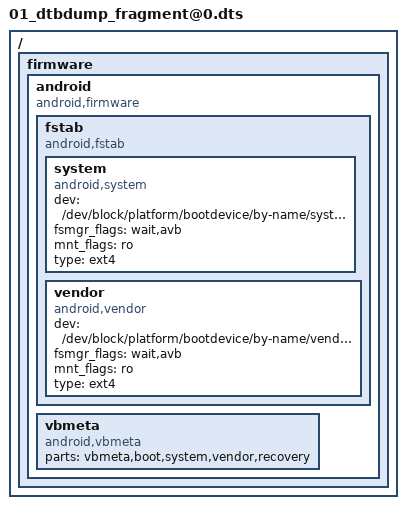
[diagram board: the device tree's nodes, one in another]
/dts-v1/;

/ {

	__fixups__ {
		accdet = "/fragment@20:target:0\0/fragment@61:target:0";
		apuart0 = "/fragment@25:target:0";
		audgpio = "/fragment@21:target:0";
		auxadc = "/fragment@40:target:0";
		charger = "/fragment@34:target:0";
		chosen = "/fragment@1:target:0";
		consys = "/fragment@24:target:0";
		dsi_te = "/fragment@66:target:0";
		egis_fp = "/fragment@4:target:0\0/fragment@64:target:0";
		gpio = "/fragment@55:target:0";
		gpio_usage_mapping = "/fragment@54:target:0";
		gyro = "/fragment@59:target:0";
		i2c0 = "/fragment@16:target:0\0/fragment@42:target:0";
		i2c1 = "/fragment@43:target:0";
		i2c10 = "/fragment@52:target:0";
		i2c11 = "/fragment@53:target:0";
		i2c2 = "/fragment@44:target:0";
		i2c3 = "/fragment@10:target:0\0/fragment@13:target:0\0/fragment@45:target:0";
		i2c4 = "/fragment@46:target:0";
		i2c5 = "/fragment@47:target:0";
		i2c6 = "/fragment@38:target:0\0/fragment@48:target:0";
		i2c7 = "/fragment@49:target:0";
		i2c8 = "/fragment@50:target:0";
		i2c9 = "/fragment@51:target:0";
		irtx_pwm = "/fragment@27:target:0";
		kd_camera_hw1 = "/fragment@78:target:0\0/fragment@82:target:0";
		keypad = "/fragment@30:target:0\0/fragment@80:target:0";
		main_pmic = "/fragment@67:target:0";
		md1_sim1_hot_plug_eint = "/fragment@69:target:0";
		md1_sim2_hot_plug_eint = "/fragment@70:target:0";
		mediatek_phy_tuning = "/fragment@8:target:0";
		mrdump_ext_rst = "/fragment@56:target:0";
		msdc1 = "/fragment@32:target:0";
		msdc1_ins = "/fragment@58:target:0";
		mse = "/fragment@60:target:0";
		mt6370_pmu = "/fragment@29:target:0";
		mt_pmic_vcama1_ldo_reg = "/fragment@71:target:0\0/fragment@78/__overlay__:vcama_main2-supply:0\0/fragment@82/__overlay__:cam2_vcama-supply:0";
		mt_pmic_vcama2_ldo_reg = "/fragment@72:target:0\0/fragment@78/__overlay__:vcama_sub-supply:0\0/fragment@82/__overlay__:cam1_vcama-supply:0";
		mt_pmic_vcamd_ldo_reg = "/fragment@75:target:0\0/fragment@78/__overlay__:vcamd-supply:0\0/fragment@82/__overlay__:cam0_vcamd-supply:0";
		mt_pmic_vcamio_ldo_reg = "/fragment@76:target:0\0/fragment@78/__overlay__:vcamio-supply:0\0/fragment@78/__overlay__:vcamio_sub-supply:0\0/fragment@78/__overlay__:vcamio_main2-supply:0\0/fragment@82/__overlay__:cam0_vcamio-supply:0\0/fragment@82/__overlay__:cam1_vcamio-supply:0\0/fragment@82/__overlay__:cam2_vcamio-supply:0";
		mt_pmic_vldo28_ldo_reg = "/fragment@77:target:0\0/fragment@78/__overlay__:vcamaf-supply:0\0/fragment@78/__overlay__:vcamaf_sub-supply:0\0/fragment@78/__overlay__:vcamaf_main2-supply:0\0/fragment@79/__overlay__:vtouch-supply:0\0/fragment@82/__overlay__:cam0_vcamaf-supply:0";
		mt_pmic_vsim1_ldo_reg = "/fragment@73:target:0";
		mt_pmic_vsim2_ldo_reg = "/fragment@74:target:0";
		mtkfb = "/fragment@12:target:0";
		odm = "/fragment@2:target:0";
		oppo_fp_common = "/fragment@7:target:0";
		otg_iddig = "/fragment@18:target:0\0/fragment@62:target:0";
		pio = "/fragment@2/__overlay__/kpd_volume_up:interrupt-parent:0\0/fragment@2/__overlay__/kpd_volume_down:interrupt-parent:0\0/fragment@2/__overlay__/oppo_devinfo:Hw,sub_hwid_1:0\0/fragment@2/__overlay__/oppo_charger:qcom,chargerid_switch-gpio:0\0/fragment@2/__overlay__/oppo_charger:qcom,ship-gpio:0\0/fragment@2/__overlay__/oppo_charger:qcom,shortc-gpio:0\0/fragment@5:target:0\0/fragment@6:target:0\0/fragment@7/__overlay__:oppo,fp-id0:0\0/fragment@11:target:0\0/fragment@14:target:0\0/fragment@15:target:0\0/fragment@16/__overlay__/dhall0-m1120@0f:interrupt-parent:0\0/fragment@16/__overlay__/dhall0-m1120@0f:dhall,irq-gpio:0\0/fragment@16/__overlay__/dhall0-m1120@0f:hall-power-gpio:0\0/fragment@16/__overlay__/dhall1-m1120@0c:interrupt-parent:0\0/fragment@16/__overlay__/dhall1-m1120@0c:dhall,irq-gpio:0\0/fragment@16/__overlay__/dhall1-m1120@0c:hall-power-gpio:0\0/fragment@17:target:0\0/fragment@19:target:0\0/fragment@22:target:0\0/fragment@23:target:0\0/fragment@26:target:0\0/fragment@28:target:0\0/fragment@29/__overlay__:mt6370,intr_gpio:0\0/fragment@30/__overlay__:keypad,volume-up:0\0/fragment@30/__overlay__:keypad,volume-down:0\0/fragment@31:target:0\0/fragment@33:target:0\0/fragment@35:target:0\0/fragment@36:target:0\0/fragment@37:target:0\0/fragment@39:target:0\0/fragment@43/__overlay__/alsps@51:interrupt-parent:0\0/fragment@54/__overlay__:GPIO_SIM2_SIO:0\0/fragment@54/__overlay__:GPIO_SIM2_SRST:0\0/fragment@54/__overlay__:GPIO_SIM2_SCLK:0\0/fragment@54/__overlay__:GPIO_SIM1_SCLK:0\0/fragment@54/__overlay__:GPIO_SIM1_SRST:0\0/fragment@54/__overlay__:GPIO_SIM1_SIO:0\0/fragment@54/__overlay__:GPIO_SIM2_HOT_PLUG:0\0/fragment@54/__overlay__:GPIO_SIM1_HOT_PLUG:0\0/fragment@54/__overlay__:GPIO_FDD_BAND_SUPPORT_DETECT_3RD_PIN:0\0/fragment@54/__overlay__:GPIO_FDD_BAND_SUPPORT_DETECT_1ST_PIN:0\0/fragment@54/__overlay__:GPIO_FDD_BAND_SUPPORT_DETECT_2ND_PIN:0\0/fragment@56/__overlay__:interrupt-parent:0\0/fragment@56/__overlay__:deb-gpios:0\0/fragment@57/__overlay__:interrupt-parent:0\0/fragment@58/__overlay__:interrupt-parent:0\0/fragment@58/__overlay__:deb-gpios:0\0/fragment@59/__overlay__:interrupt-parent:0\0/fragment@60/__overlay__:interrupt-parent:0\0/fragment@61/__overlay__:interrupt-parent:0\0/fragment@61/__overlay__:deb-gpios:0\0/fragment@62/__overlay__:interrupt-parent:0\0/fragment@63/__overlay__:interrupt-parent:0\0/fragment@64/__overlay__:interrupt-parent:0\0/fragment@65/__overlay__:interrupt-parent:0\0/fragment@66/__overlay__:interrupt-parent:0\0/fragment@67/__overlay__:interrupt-parent:0\0/fragment@68/__overlay__:interrupt-parent:0\0/fragment@81:target:0";
		pmic_clock_buffer_ctrl = "/fragment@41:target:0";
		reserved_memory = "/fragment@0:target:0";
		scp = "/fragment@9:target:0";
		smart_pa = "/fragment@68:target:0";
		spi0 = "/fragment@3:target:0";
		subpmic_pmu_eint = "/fragment@63:target:0";
		tcpc_pd = "/fragment@65:target:0";
		touch = "/fragment@57:target:0\0/fragment@79:target:0";
	};

	__local_fixups__ {

		fragment@12 {

			__overlay__ {
				pinctrl-0 = <0x00>;
				pinctrl-1 = <0x00>;
			};
		};

		fragment@13 {

			__overlay__ {

				tfa98xx@35 {
					pinctrl-0 = <0x00>;
					pinctrl-1 = <0x00>;
					pinctrl-2 = <0x00>;
				};
			};
		};

		fragment@16 {

			__overlay__ {

				dhall0-m1120@0f {
					pinctrl-0 = <0x00>;
					pinctrl-1 = <0x00>;
					pinctrl-2 = <0x00>;
				};

				dhall1-m1120@0c {
					pinctrl-0 = <0x00>;
					pinctrl-1 = <0x00>;
					pinctrl-2 = <0x00>;
				};
			};
		};

		fragment@18 {

			__overlay__ {
				pinctrl-0 = <0x00>;
				pinctrl-1 = <0x00>;
				pinctrl-2 = <0x00>;
				pinctrl-3 = <0x00>;
			};
		};

		fragment@2 {

			__overlay__ {

				oppo_charger {
					pinctrl-0 = <0x00>;
					pinctrl-1 = <0x00>;
					pinctrl-2 = <0x00>;
					pinctrl-3 = <0x00>;
					pinctrl-4 = <0x00>;
					pinctrl-5 = <0x00>;
				};

				oppo_devinfo {
					pinctrl-0 = <0x00>;
					pinctrl-1 = <0x00>;
					pinctrl-2 = <0x00>;
				};
			};
		};

		fragment@21 {

			__overlay__ {
				pinctrl-0 = <0x00>;
				pinctrl-1 = <0x00>;
				pinctrl-10 = <0x00>;
				pinctrl-11 = <0x00>;
				pinctrl-2 = <0x00>;
				pinctrl-3 = <0x00>;
				pinctrl-4 = <0x00>;
				pinctrl-5 = <0x00>;
				pinctrl-6 = <0x00>;
				pinctrl-7 = <0x00>;
				pinctrl-8 = <0x00>;
				pinctrl-9 = <0x00>;
			};
		};

		fragment@24 {

			__overlay__ {
				pinctrl-0 = <0x00>;
				pinctrl-1 = <0x00>;
				pinctrl-2 = <0x00>;
				pinctrl-3 = <0x00>;
			};
		};

		fragment@25 {

			__overlay__ {
				pinctrl-0 = <0x00>;
				pinctrl-1 = <0x00>;
				pinctrl-2 = <0x00>;
				pinctrl-3 = <0x00>;
				pinctrl-4 = <0x00>;
				pinctrl-5 = <0x00>;
				pinctrl-6 = <0x00>;
			};
		};

		fragment@27 {

			__overlay__ {
				pinctrl-0 = <0x00>;
				pinctrl-1 = <0x00>;
			};
		};

		fragment@30 {

			__overlay__ {
				pinctrl-0 = <0x00>;
				pinctrl-1 = <0x00>;
			};
		};

		fragment@32 {

			__overlay__ {
				pinctrl-0 = <0x00>;
				pinctrl-1 = <0x00>;
			};
		};

		fragment@38 {

			__overlay__ {
				pinctrl-0 = <0x00>;
				pinctrl-1 = <0x00>;
			};
		};

		fragment@4 {

			__overlay__ {
				pinctrl-0 = <0x00>;
				pinctrl-1 = <0x00>;
				pinctrl-2 = <0x00>;
				pinctrl-3 = <0x00>;
			};
		};

		fragment@7 {

			__overlay__ {
				pinctrl-0 = <0x00>;
			};
		};

		fragment@82 {

			__overlay__ {
				pinctrl-0 = <0x00>;
				pinctrl-1 = <0x00>;
				pinctrl-10 = <0x00>;
				pinctrl-11 = <0x00>;
				pinctrl-12 = <0x00>;
				pinctrl-13 = <0x00>;
				pinctrl-14 = <0x00>;
				pinctrl-15 = <0x00>;
				pinctrl-16 = <0x00>;
				pinctrl-17 = <0x00>;
				pinctrl-18 = <0x00>;
				pinctrl-19 = <0x00>;
				pinctrl-2 = <0x00>;
				pinctrl-20 = <0x00>;
				pinctrl-21 = <0x00>;
				pinctrl-22 = <0x00>;
				pinctrl-23 = <0x00>;
				pinctrl-24 = <0x00>;
				pinctrl-25 = <0x00>;
				pinctrl-26 = <0x00>;
				pinctrl-27 = <0x00>;
				pinctrl-28 = <0x00>;
				pinctrl-29 = <0x00>;
				pinctrl-3 = <0x00>;
				pinctrl-30 = <0x00>;
				pinctrl-31 = <0x00>;
				pinctrl-32 = <0x00>;
				pinctrl-33 = <0x00>;
				pinctrl-4 = <0x00>;
				pinctrl-5 = <0x00>;
				pinctrl-6 = <0x00>;
				pinctrl-7 = <0x00>;
				pinctrl-8 = <0x00>;
				pinctrl-9 = <0x00>;
			};
		};
	};

	__symbols__ {
		alsps_mtk = "/fragment@43/__overlay__/alsps@51";
		aud_clk_mosi_off = "/fragment@22/__overlay__/aud_clk_mosi_off";
		aud_clk_mosi_on = "/fragment@22/__overlay__/aud_clk_mosi_on";
		aud_dat_miso_off = "/fragment@22/__overlay__/aud_dat_miso_off";
		aud_dat_miso_on = "/fragment@22/__overlay__/aud_dat_miso_on";
		aud_dat_mosi_off = "/fragment@22/__overlay__/aud_dat_mosi_off";
		aud_dat_mosi_on = "/fragment@22/__overlay__/aud_dat_mosi_on";
		aud_extamp_pullhigh = "/fragment@22/__overlay__/aud_extamp_pullhigh";
		aud_extamp_pulllow = "/fragment@22/__overlay__/aud_extamp_pulllow";
		barometer_mtk = "/fragment@43/__overlay__/barometer@77";
		bat_gm30 = "/fragment@2/__overlay__/battery";
		camera_main_af_mtk = "/fragment@44/__overlay__/camera_main_af@72";
		camera_main_eeprom_mtk = "/fragment@44/__overlay__/camera_main_eeprom@50";
		camera_main_mtk = "/fragment@44/__overlay__/camera_main@1a";
		camera_main_two_af_mtk = "/fragment@46/__overlay__/camera_main_two_af@72";
		camera_main_two_eeprom_mtk = "/fragment@46/__overlay__/camera_main_two_eeprom@51";
		camera_main_two_mtk = "/fragment@46/__overlay__/camera_main_two@10";
		camera_pins_cam0_mclk_2ma = "/fragment@81/__overlay__/camera0_mclk_2mA@gpio99";
		camera_pins_cam0_mclk_4ma = "/fragment@81/__overlay__/camera0_mclk_4mA@gpio99";
		camera_pins_cam0_mclk_6ma = "/fragment@81/__overlay__/camera0_mclk_6mA@gpio99";
		camera_pins_cam0_mclk_8ma = "/fragment@81/__overlay__/camera0_mclk_8mA@gpio99";
		camera_pins_cam0_mclk_off = "/fragment@81/__overlay__/camera0_mclk_gpio_mode@gpio99";
		camera_pins_cam0_pnd_0 = "/fragment@81/__overlay__/cam0@2";
		camera_pins_cam0_pnd_1 = "/fragment@81/__overlay__/cam0@3";
		camera_pins_cam0_rst_0 = "/fragment@81/__overlay__/cam0@0";
		camera_pins_cam0_rst_1 = "/fragment@81/__overlay__/cam0@1";
		camera_pins_cam0_vcama_0 = "/fragment@81/__overlay__/cam0@vcam0";
		camera_pins_cam0_vcama_1 = "/fragment@81/__overlay__/cam0@vcam1";
		camera_pins_cam1_mclk_2ma = "/fragment@81/__overlay__/camera1_mclk_2mA@gpio100";
		camera_pins_cam1_mclk_4ma = "/fragment@81/__overlay__/camera1_mclk_4mA@gpio100";
		camera_pins_cam1_mclk_6ma = "/fragment@81/__overlay__/camera1_mclk_6mA@gpio100";
		camera_pins_cam1_mclk_8ma = "/fragment@81/__overlay__/camera1_mclk_8mA@gpio100";
		camera_pins_cam1_mclk_off = "/fragment@81/__overlay__/camera1_mclk_gpio_mode@gpio100";
		camera_pins_cam1_pdn_0 = "/fragment@81/__overlay__/cam1@0";
		camera_pins_cam1_pdn_1 = "/fragment@81/__overlay__/cam1@1";
		camera_pins_cam1_rst_0 = "/fragment@81/__overlay__/cam1@2";
		camera_pins_cam1_rst_1 = "/fragment@81/__overlay__/cam1@3";
		camera_pins_cam1_vcamd_0 = "/fragment@81/__overlay__/cam1@vcam0";
		camera_pins_cam1_vcamd_1 = "/fragment@81/__overlay__/cam1@vcam1";
		camera_pins_cam2_mclk_2ma = "/fragment@81/__overlay__/camera2_mclk_2mA@gpio108";
		camera_pins_cam2_mclk_4ma = "/fragment@81/__overlay__/camera2_mclk_4mA@gpio108";
		camera_pins_cam2_mclk_6ma = "/fragment@81/__overlay__/camera2_mclk_6mA@gpio108";
		camera_pins_cam2_mclk_8ma = "/fragment@81/__overlay__/camera2_mclk_8mA@gpio108";
		camera_pins_cam2_mclk_off = "/fragment@81/__overlay__/camera2_mclk_gpio_mode@gpio108";
		camera_pins_cam2_pnd_0 = "/fragment@81/__overlay__/cam2@3";
		camera_pins_cam2_pnd_1 = "/fragment@81/__overlay__/cam2@4";
		camera_pins_cam2_rst_0 = "/fragment@81/__overlay__/cam2@0";
		camera_pins_cam2_rst_1 = "/fragment@81/__overlay__/cam2@1";
		camera_pins_cami2c_pullup_disable = "/fragment@81/__overlay__/camera_pins_cami2c_pullup_disable@i2c";
		camera_pins_cami2c_pullup_enable = "/fragment@81/__overlay__/camera_pins_cami2c_pullup_enable@i2c";
		camera_pins_default = "/fragment@81/__overlay__/camdefault";
		camera_sub_eeprom_mtk = "/fragment@46/__overlay__/camera_sub_eeprom@54";
		camera_sub_mtk = "/fragment@46/__overlay__/camera_sub@35";
		cap_touch_mtk = "/fragment@42/__overlay__/cap_touch@5d";
		ccu_sensor_i2c_2_hw_mtk = "/fragment@44/__overlay__/ccu_sensor_i2c_2_hw@33";
		ccu_sensor_i2c_4_hw_mtk = "/fragment@46/__overlay__/ccu_sensor_i2c_4_hw@36";
		charger_pins_default = "/fragment@35/__overlay__/eint0default";
		charger_pins_eint_output0 = "/fragment@35/__overlay__/charger_gpio_as_output_low";
		charger_pins_eint_output1 = "/fragment@35/__overlay__/charger_gpio_as_output_high";
		charging_clock_active = "/fragment@36/__overlay__/charging_clock_active";
		charging_clock_sleep = "/fragment@36/__overlay__/charging_clock_sleep";
		charging_data_active = "/fragment@36/__overlay__/charging_data_active";
		charging_data_sleep = "/fragment@36/__overlay__/charging_data_sleep";
		charging_reset_active = "/fragment@36/__overlay__/charging_reset_active";
		charging_reset_sleep = "/fragment@36/__overlay__/charging_reset_sleep";
		charging_switch1_active = "/fragment@36/__overlay__/charging_switch1_active";
		charging_switch1_sleep = "/fragment@36/__overlay__/charging_switch1_sleep";
		consys_pins_default = "/fragment@23/__overlay__/consys_default";
		ctp_pins_default = "/fragment@15/__overlay__/eint0default";
		ctp_pins_eint_as_int = "/fragment@15/__overlay__/eint@0";
		ctp_pins_eint_output0 = "/fragment@15/__overlay__/eintoutput0";
		ctp_pins_eint_output1 = "/fragment@15/__overlay__/eintoutput1";
		ctp_pins_rst_output0 = "/fragment@15/__overlay__/rstoutput0";
		ctp_pins_rst_output1 = "/fragment@15/__overlay__/rstoutput1";
		fuelgauge = "/fragment@2/__overlay__/fuelgauge";
		gpio42_output_high = "/fragment@19/__overlay__/gpio42_output_high";
		gpio9_gpio_mode = "/fragment@19/__overlay__/id_output_low";
		gpio9_mode1_iddig = "/fragment@19/__overlay__/id_init";
		gpio_id0_default = "/fragment@6/__overlay__/gpio_id0_default";
		gpslna_pins_init = "/fragment@23/__overlay__/gpslna@0";
		gpslna_pins_oh = "/fragment@23/__overlay__/gpslna@1";
		gpslna_pins_ol = "/fragment@23/__overlay__/gpslna@2";
		hall0_interrupt_input = "/fragment@17/__overlay__/hall0_interrupt_input";
		hall1_interrupt_input = "/fragment@17/__overlay__/hall1_interrupt_input";
		hall_power_down = "/fragment@17/__overlay__/hall_power_down";
		hall_power_up = "/fragment@17/__overlay__/hall_power_up";
		hw_pins_default = "/fragment@37/__overlay__/default@hw_sub_id";
		hw_pins_sub_id1_active = "/fragment@37/__overlay__/active@id1";
		hw_pins_sub_id1_sleep = "/fragment@37/__overlay__/sleep@id1";
		i2c6_i2c_state = "/fragment@39/__overlay__/i2c6_sda_i2c_state";
		i2c6_output_low_state = "/fragment@39/__overlay__/i2c6_sda_output_low_state";
		iddig_default = "/fragment@19/__overlay__/iddig_default";
		irtx_gpio_led_default = "/fragment@28/__overlay__/irtx_gpio_led_def@gpio90";
		irtx_gpio_led_set = "/fragment@28/__overlay__/irtx_gpio_led_set@gpio90";
		kpd_volume_down = "/fragment@2/__overlay__/kpd_volume_down";
		kpd_volume_up = "/fragment@2/__overlay__/kpd_volume_up";
		led0 = "/fragment@2/__overlay__/led@0";
		led1 = "/fragment@2/__overlay__/led@1";
		led2 = "/fragment@2/__overlay__/led@2";
		led3 = "/fragment@2/__overlay__/led@3";
		led4 = "/fragment@2/__overlay__/led@4";
		led5 = "/fragment@2/__overlay__/led@5";
		led6 = "/fragment@2/__overlay__/led@6";
		msdc1_off = "/fragment@33/__overlay__/sd0@1";
		msdc1_on = "/fragment@33/__overlay__/sd0@0";
		msensor_mtk = "/fragment@43/__overlay__/msensor@0c";
		mtkfb_pins_lcd_1p8_en0 = "/fragment@11/__overlay__/lcd_1p8_en0_gpio";
		mtkfb_pins_lcd_1p8_en1 = "/fragment@11/__overlay__/lcd_1p8_en1_gpio";
		mtkfb_pins_lcd_bias_enn0 = "/fragment@11/__overlay__/lcd_bias_enn0_gpio";
		mtkfb_pins_lcd_bias_enn1 = "/fragment@11/__overlay__/lcd_bias_enn1_gpio";
		mtkfb_pins_lcd_bias_enp0 = "/fragment@11/__overlay__/lcd_bias_enp0_gpio";
		mtkfb_pins_lcd_bias_enp1 = "/fragment@11/__overlay__/lcd_bias_enp1_gpio";
		mtkfb_pins_lcd_bl_en0 = "/fragment@11/__overlay__/lcd_bl_en0_gpio";
		mtkfb_pins_lcd_bl_en1 = "/fragment@11/__overlay__/lcd_bl_en1_gpio";
		mtkfb_pins_lcm_reset0 = "/fragment@11/__overlay__/lcm_rst_out0_gpio";
		mtkfb_pins_lcm_reset1 = "/fragment@11/__overlay__/lcm_rst_out1_gpio";
		mtkfb_pins_mode_te_gpio = "/fragment@11/__overlay__/mode_te_gpio";
		mtkfb_pins_mode_te_te = "/fragment@11/__overlay__/mode_te_te";
		mtkfb_pins_spi_clk_en0 = "/fragment@11/__overlay__/spi_clk_en0_gpio";
		mtkfb_pins_spi_clk_en1 = "/fragment@11/__overlay__/spi_clk_en1_gpio";
		mtkfb_pins_spi_cs_en0 = "/fragment@11/__overlay__/spi_csn_en0_gpio";
		mtkfb_pins_spi_cs_en1 = "/fragment@11/__overlay__/spi_csn_en1_gpio";
		nfc_mtk = "/fragment@45/__overlay__/nfc@08";
		oppo_charger = "/fragment@2/__overlay__/oppo_charger";
		oppo_devinfo = "/fragment@2/__overlay__/oppo_devinfo";
		oppo_project = "/fragment@2/__overlay__/oppo_project";
		oppo_sensor = "/fragment@2/__overlay__/oppo_sensor";
		ship_active_gpio = "/fragment@35/__overlay__/ship_active";
		ship_sleep_gpio = "/fragment@35/__overlay__/ship_sleep";
		shortc_active_gpio = "/fragment@35/__overlay__/shortc_active";
		silfp_default = "/fragment@5/__overlay__/silfpdefault";
		silfp_irq = "/fragment@5/__overlay__/fp_eint@8";
		silfp_rst_high = "/fragment@5/__overlay__/state_reset_high";
		silfp_rst_low = "/fragment@5/__overlay__/state_reset_low";
		slave_charger_mtk = "/fragment@48/__overlay__/slave_charger@4b";
		speaker_amp_mtk = "/fragment@48/__overlay__/speaker_amp@34";
		subpmic_pmu_mtk = "/fragment@47/__overlay__/subpmic_pmu@34";
		tfa98xxresetdefault = "/fragment@14/__overlay__/tfa98xxrstdefault";
		tfa98xxresethigh = "/fragment@14/__overlay__/tfa98xxrsthigh";
		tfa98xxresetlow = "/fragment@14/__overlay__/tfa98xxrstlow";
		uart0_gpio_def_cfg = "/fragment@26/__overlay__/uart0gpiodefault";
		uart0_rx_clr_cfg = "/fragment@26/__overlay__/uart0_rx_clear@gpio95";
		uart0_rx_gpio_input = "/fragment@26/__overlay__/uart0_rx_gpio@gpio95";
		uart0_rx_set_cfg = "/fragment@26/__overlay__/uart0_rx_set@gpio95";
		uart0_tx_clr_cfg = "/fragment@26/__overlay__/uart0_tx_clear@gpio96";
		uart0_tx_gpio_input = "/fragment@26/__overlay__/uart0_tx_gpio@gpio96";
		uart0_tx_set_cfg = "/fragment@26/__overlay__/uart0_tx_set@gpio96";
		usb_c_pinctrl = "/fragment@2/__overlay__/usb_c_pinctrl";
		usb_type_c_mtk = "/fragment@47/__overlay__/usb_type_c@4e";
		vibrator0 = "/fragment@2/__overlay__/vibrator@0";
		volume_down_gpio_eint = "/fragment@31/__overlay__/volume_down@0";
		volume_up_gpio_eint = "/fragment@31/__overlay__/volume_up@0";
		vooc_ap_data = "/fragment@2/__overlay__/vooc_ap_data";
		vooc_ap_data_new_function = "/fragment@2/__overlay__/vooc_ap_data_new_function";
		vow_clk_miso_off = "/fragment@22/__overlay__/vow_clk_miso_off";
		vow_clk_miso_on = "/fragment@22/__overlay__/vow_clk_miso_on";
		vow_dat_miso_off = "/fragment@22/__overlay__/vow_dat_miso_off";
		vow_dat_miso_on = "/fragment@22/__overlay__/vow_dat_miso_on";
	};

	firmware {

		android {
			compatible = "android,firmware";

			fstab {
				compatible = "android,fstab";

				system {
					compatible = "android,system";
					dev = "/dev/block/platform/bootdevice/by-name/system";
					fsmgr_flags = "wait,avb";
					mnt_flags = "ro";
					type = "ext4";
				};

				vendor {
					compatible = "android,vendor";
					dev = "/dev/block/platform/bootdevice/by-name/vendor";
					fsmgr_flags = "wait,avb";
					mnt_flags = "ro";
					type = "ext4";
				};
			};

			vbmeta {
				compatible = "android,vbmeta";
				parts = "vbmeta,boot,system,vendor,recovery";
			};
		};
	};

	fragment@0 {
		target = <0xffffffff>;

		__overlay__ {
			#address-cells = <0x02>;
			#size-cells = <0x02>;
			ranges;

			zmc-default {
				alignment = <0x00 0x10000000>;
				alloc-ranges = <0x01 0x00 0x01 0x00>;
				compatible = "mediatek,zone_movable_cma";
				size = <0x00 0xffc00000>;
			};
		};
	};

	fragment@1 {
		target = <0xffffffff>;

		__overlay__ {
			atag,videolfb-fb_base_h = <0x00>;
			atag,videolfb-fb_base_l = "^`P";
			atag,videolfb-fps = <0x1770>;
			atag,videolfb-islcm_inited = <0x00>;
			atag,videolfb-islcmfound = <0x01>;
			atag,videolfb-lcmname = "nt35595_fhd_dsi_cmd_truly_nt50358_drv";
			atag,videolfb-vramSize = <0x17bb000>;
		};
	};

	fragment@10 {
		target = <0xffffffff>;

		__overlay__ {
			#address-cells = <0x01>;
			#size-cells = <0x00>;

			i2c_bl_lm3697@36 {
				compatible = "mediatek,i2c_bl_lm3697";
				reg = <0x36>;
				status = "okay";
			};

			i2c_lcd_bias@3e {
				compatible = "mediatek,i2c_lcd_bias";
				reg = <0x3e>;
				status = "okay";
			};
		};
	};

	fragment@11 {
		target = <0xffffffff>;

		__overlay__ {

			lcd_1p8_en0_gpio {
				phandle = <0x78>;

				pins_cmd_dat {
					output-low;
					pinmux = <0x2e00>;
					slew-rate = <0x01>;
				};
			};

			lcd_1p8_en1_gpio {
				phandle = <0x79>;

				pins_cmd_dat {
					output-high;
					pinmux = <0x2e00>;
					slew-rate = <0x01>;
				};
			};

			lcd_bias_enn0_gpio {
				phandle = <0x74>;

				pins_cmd_dat {
					output-low;
					pinmux = <0xb200>;
					slew-rate = <0x01>;
				};
			};

			lcd_bias_enn1_gpio {
				phandle = <0x75>;

				pins_cmd_dat {
					output-high;
					pinmux = <0xb200>;
					slew-rate = <0x01>;
				};
			};

			lcd_bias_enp0_gpio {
				phandle = <0x72>;

				pins_cmd_dat {
					output-low;
					pinmux = <0x9f00>;
					slew-rate = <0x01>;
				};
			};

			lcd_bias_enp1_gpio {
				phandle = <0x73>;

				pins_cmd_dat {
					output-high;
					pinmux = <0x9f00>;
					slew-rate = <0x01>;
				};
			};

			lcd_bl_en0_gpio {
				phandle = <0x76>;

				pins_cmd_dat {
					output-low;
					pinmux = <0xaf00>;
					slew-rate = <0x01>;
				};
			};

			lcd_bl_en1_gpio {
				phandle = <0x77>;

				pins_cmd_dat {
					output-high;
					pinmux = <0xaf00>;
					slew-rate = <0x01>;
				};
			};

			lcm_rst_out0_gpio {
				phandle = <0x0f>;

				pins_cmd_dat {
					output-low;
					pinmux = <0x2d00>;
					slew-rate = <0x01>;
				};
			};

			lcm_rst_out1_gpio {
				phandle = <0x10>;

				pins_cmd_dat {
					output-high;
					pinmux = <0x2d00>;
					slew-rate = <0x01>;
				};
			};

			mode_te_gpio {
				phandle = <0x70>;

				pins_cmd_dat {
					pinmux = <0x2c00>;
				};
			};

			mode_te_te {
				phandle = <0x71>;

				pins_cmd_dat {
					pinmux = <0x2c01>;
				};
			};

			spi_clk_en0_gpio {
				phandle = <0x7d>;

				pins_cmd_dat {
					output-low;
					pinmux = <0x1800>;
					slew-rate = <0x01>;
				};
			};

			spi_clk_en1_gpio {
				phandle = <0x7c>;

				pins_cmd_dat {
					drive-strength = <0x00>;
					pinmux = <0x1802>;
				};
			};

			spi_csn_en0_gpio {
				phandle = <0x7b>;

				pins_cmd_dat {
					output-low;
					pinmux = <0x1600>;
					slew-rate = <0x01>;
				};
			};

			spi_csn_en1_gpio {
				phandle = <0x7a>;

				pins_cmd_dat {
					drive-strength = <0x00>;
					output-high;
					pinmux = <0x1602>;
				};
			};
		};
	};

	fragment@12 {
		target = <0xffffffff>;

		__overlay__ {
			oppo_display_cabc_support;
			oppo_display_ffl_support;
			pinctrl-0 = <0x0f>;
			pinctrl-1 = <0x10>;
			pinctrl-names = "lcm_rst_out0_gpio\0lcm_rst_out1_gpio";
			status = "okay";
		};
	};

	fragment@13 {
		target = <0xffffffff>;

		__overlay__ {
			#address-cells = <0x01>;
			#size-cells = <0x00>;

			tfa98xx@35 {
				compatible = "nxp,tfa98xx";
				pinctrl-0 = <0x11>;
				pinctrl-1 = <0x12>;
				pinctrl-2 = <0x13>;
				pinctrl-names = "tfa98xx_reset_default\0tfa98xx_reset_high\0tfa98xx_reset_low";
				reg = <0x35>;
				status = "okay";
			};
		};
	};

	fragment@14 {
		target = <0xffffffff>;

		__overlay__ {

			tfa98xxrstdefault {
				phandle = <0x11>;
			};

			tfa98xxrsthigh {
				phandle = <0x12>;

				pins_cmd_dat {
					output-high;
					pinmux = <0x9c00>;
					slew-rate = <0x01>;
				};
			};

			tfa98xxrstlow {
				phandle = <0x13>;

				pins_cmd_dat {
					output-low;
					pinmux = <0x9c00>;
					slew-rate = <0x01>;
				};
			};
		};
	};

	fragment@15 {
		target = <0xffffffff>;

		__overlay__ {

			eint0default {
				phandle = <0x7e>;
			};

			eint@0 {
				phandle = <0x7f>;

				pins_cmd_dat {
					bias-disable;
					pinmux = <0x100>;
					slew-rate = <0x00>;
				};
			};

			eintoutput0 {
				phandle = <0x80>;

				pins_cmd_dat {
					output-low;
					pinmux = <0x100>;
					slew-rate = <0x01>;
				};
			};

			eintoutput1 {
				phandle = <0x81>;

				pins_cmd_dat {
					output-high;
					pinmux = <0x100>;
					slew-rate = <0x01>;
				};
			};

			rstoutput0 {
				phandle = <0x82>;

				pins_cmd_dat {
					output-low;
					pinmux = <0x200>;
					slew-rate = <0x01>;
				};
			};

			rstoutput1 {
				phandle = <0x83>;

				pins_cmd_dat {
					output-high;
					pinmux = <0x200>;
					slew-rate = <0x01>;
				};
			};
		};
	};

	fragment@16 {
		target = <0xffffffff>;

		__overlay__ {
			status = "ok";

			dhall0-m1120@0f {
				compatible = "oppo,dhall-m1120";
				dhall,id = <0x00>;
				dhall,irq-gpio = <0xffffffff 0x05 0x2008>;
				hall-power-gpio = <0xffffffff 0x6e 0x00>;
				interrupt-parent = <0xffffffff>;
				interrupts = <0x05 0x08 0x05 0x00>;
				pinctrl-0 = <0x14>;
				pinctrl-1 = <0x15>;
				pinctrl-2 = <0x16>;
				pinctrl-names = "hall_power_down\0hall_power_up\0hall0_interrupt_input";
				reg = <0x0f>;
				status = "okay";
			};

			dhall1-m1120@0c {
				compatible = "oppo,dhall-m1120";
				dhall,id = <0x01>;
				dhall,irq-gpio = <0xffffffff 0x06 0x2008>;
				hall-power-gpio = <0xffffffff 0x6e 0x00>;
				interrupt-parent = <0xffffffff>;
				interrupts = <0x06 0x08 0x06 0x00>;
				pinctrl-0 = <0x14>;
				pinctrl-1 = <0x15>;
				pinctrl-2 = <0x17>;
				pinctrl-names = "hall_power_down\0hall_power_up\0hall1_interrupt_input";
				reg = <0x0c>;
				status = "okay";
			};
		};
	};

	fragment@17 {
		target = <0xffffffff>;

		__overlay__ {

			hall0_interrupt_input {
				phandle = <0x16>;

				pins_cmd_dat {
					bias-disable;
					drive-strength = <0x02>;
					pinmux = <0x600>;
					slew-rate = <0x00>;
				};
			};

			hall1_interrupt_input {
				phandle = <0x17>;

				pins_cmd_dat {
					bias-disable;
					drive-strength = <0x02>;
					pinmux = <0x500>;
					slew-rate = <0x00>;
				};
			};

			hall_power_down {
				phandle = <0x14>;

				pins_cmd_dat {
					bias-pull-down;
					drive-strength = <0x02>;
					output-low;
					pinmux = <0x6e00>;
					slew-rate = <0x01>;
				};
			};

			hall_power_up {
				phandle = <0x15>;

				pins_cmd_dat {
					bias-pull-down;
					drive-strength = <0x02>;
					output-high;
					pinmux = <0x6e00>;
					slew-rate = <0x01>;
				};
			};
		};
	};

	fragment@18 {
		target = <0xffffffff>;

		__overlay__ {
			compatible = "mediatek,usb_iddig_bi_eint";
			pinctrl-0 = <0x18>;
			pinctrl-1 = <0x19>;
			pinctrl-2 = <0x1a>;
			pinctrl-3 = <0x1b>;
			pinctrl-names = "iddig_default\0id_init\0id_output_low\0gpio42_output_high";
			qcom,otg_switch_gpio = <0x09>;
			status = "okay";
		};
	};

	fragment@19 {
		target = <0xffffffff>;

		__overlay__ {

			gpio42_output_high {
				phandle = <0x1b>;

				pins_cmd_dat {
					output-high;
					pinmux = <0x2a00>;
					slew-rate = <0x01>;
				};
			};

			id_init {
				phandle = <0x19>;

				pins_cmd_dat {
					pinmux = <0x900>;
					slew-rate = <0x00>;
				};
			};

			id_output_low {
				phandle = <0x1a>;

				pins_cmd_dat {
					output-low;
					pinmux = <0x900>;
					slew-rate = <0x01>;
				};
			};

			iddig_default {
				phandle = <0x18>;
			};
		};
	};

	fragment@2 {
		target = <0xffffffff>;

		__overlay__ {

			battery {
				CAR_TUNE_VALUE = <0x64>;
				DIFFERENCE_FULLOCV_ITH = <0xc8>;
				EMBEDDED_SEL = <0x01>;
				FG_METER_RESISTANCE = <0x4b>;
				KEEP_100_PERCENT = <0x02>;
				PMIC_MIN_VOL = <0x84d0>;
				PMIC_SHUTDOWN_CURRENT = <0x14>;
				POWERON_SYSTEM_IBOOT = <0x1f4>;
				Q_MAX_SYS_VOLTAGE_BAT0 = <0xd16>;
				Q_MAX_SYS_VOLTAGE_BAT1 = <0xd16>;
				Q_MAX_SYS_VOLTAGE_BAT2 = <0xd16>;
				Q_MAX_SYS_VOLTAGE_BAT3 = <0xd16>;
				R_FG_VALUE = <0x0a>;
				SHUTDOWN_1_TIME = <0x1e>;
				SHUTDOWN_GAUGE0_VOLTAGE = <0x84d0>;
				TEMPERATURE_T0 = <0x32>;
				TEMPERATURE_T1 = <0x19>;
				TEMPERATURE_T2 = <0x0a>;
				TEMPERATURE_T3 = <0x00>;
				TEMPERATURE_T4 = <0xfffffff6>;
				battery0_profile_t0 = <0x00 0xaa96 0x406 0x1a9 0xaa0e 0x402 0x352 0xa994 0x413 0x4fb 0xa91d 0x41a 0x6a5 0xa8a2 0x410 0x84e 0xa827 0x407 0x9f7 0xa7b8 0x41d 0xba0 0xa741 0x432 0xd49 0xa6c2 0x40b 0xef2 0xa649 0x411 0x109c 0xa5d2 0x41a 0x1245 0xa55e 0x423 0x13ee 0xa4ed 0x433 0x1597 0xa476 0x432 0x1740 0xa3ff 0x41c 0x18e9 0xa390 0x42d 0x1a92 0xa31b 0x433 0x1c3c 0xa2a9 0x433 0x1de5 0xa23a 0x43b 0x1f8e 0xa1cc 0x44c 0x2137 0xa15d 0x44c 0x22e0 0xa0ef 0x44c 0x2489 0xa07e 0x44c 0x2632 0xa015 0x45a 0x27dc 0x9faf 0x465 0x2985 0x9f46 0x45e 0x2b2e 0x9eda 0x452 0x2cd7 0x9e7c 0x47d 0x2e80 0x9e1f 0x47e 0x3029 0x9dbb 0x47e 0x31d3 0x9d5a 0x48b 0x337c 0x9cf8 0x497 0x3525 0x9c97 0x49d 0x36ce 0x9c42 0x4b0 0x3877 0x9bed 0x4b0 0x3a20 0x9ba0 0x4d7 0x3bc9 0x9b4d 0x4f2 0x3d73 0x9af8 0x4fb 0x3f1c 0x9aa3 0x503 0x40c5 0x9a4c 0x519 0x426e 0x99ee 0x52b 0x4417 0x9976 0x4eb 0x45c0 0x98e9 0x499 0x476a 0x986a 0x452 0x4913 0x9805 0x433 0x4abc 0x97b2 0x433 0x4c65 0x9767 0x430 0x4e0e 0x9723 0x41a 0x4fb7 0x96e8 0x41a 0x5160 0x96ac 0x41a 0x530a 0x9676 0x41a 0x54b3 0x9643 0x424 0x565c 0x9610 0x42d 0x5805 0x95dd 0x41c 0x59ae 0x95aa 0x431 0x5b57 0x957f 0x433 0x5d00 0x9554 0x433 0x5eaa 0x952a 0x43f 0x6053 0x9502 0x44c 0x61fc 0x94df 0x44c 0x63a5 0x94b4 0x44d 0x654e 0x9492 0x462 0x66f7 0x9470 0x477 0x68a1 0x9454 0x48d 0x6a4a 0x9436 0x497 0x6bf3 0x9414 0x497 0x6d9c 0x93f3 0x49b 0x6f45 0x93da 0x4b0 0x70ee 0x93b8 0x4b0 0x7297 0x9387 0x49e 0x7441 0x9343 0x46d 0x75ea 0x92fb 0x44c 0x7793 0x92bc 0x44c 0x793c 0x928a 0x44c 0x7ae5 0x9260 0x44c 0x7c8e 0x9235 0x44c 0x7e38 0x9204 0x43b 0x7fe1 0x91db 0x440 0x818a 0x91b9 0x44c 0x8333 0x9197 0x451 0x84dc 0x9174 0x463 0x8685 0x9141 0x44e 0x882e 0x9106 0x44c 0x89d8 0x90cb 0x44c 0x8b81 0x9094 0x458 0x8d2a 0x9058 0x45d 0x8ed3 0x900d 0x444 0x907c 0x8fca 0x41a 0x9225 0x8fb9 0x430 0x93ce 0x8faf 0x445 0x9578 0x8fa6 0x468 0x9721 0x8f95 0x493 0x98ca 0x8f71 0x4bd 0x9a73 0x8f18 0x4d6 0x9c1c 0x8e08 0x481 0x9dc5 0x8c44 0x492 0x9f6f 0x89fa 0x4c9 0xa118 0x86c7 0x523 0xa2c1 0x815c 0x76e 0xa46a 0x774c 0x18e7>;
				battery0_profile_t0_num = <0x64>;
				battery0_profile_t1 = <0x00 0xaa32 0x564 0x1a9 0xa9a1 0x560 0x352 0xa91f 0x55f 0x4fb 0xa8a5 0x56d 0x6a5 0xa82a 0x56e 0x84e 0xa7af 0x565 0x9f7 0xa740 0x578 0xba0 0xa6c9 0x578 0xd49 0xa652 0x578 0xef2 0xa5db 0x578 0x109c 0xa564 0x578 0x1245 0xa4f0 0x578 0x13ee 0xa47f 0x578 0x1597 0xa409 0x579 0x1740 0xa39a 0x58f 0x18e9 0xa32c 0x591 0x1a92 0xa2bd 0x5a0 0x1c3c 0xa24f 0x5aa 0x1de5 0xa1dd 0x5aa 0x1f8e 0xa169 0x5ae 0x2137 0xa103 0x5c3 0x22e0 0xa095 0x5c3 0x2489 0xa02b 0x5d5 0x2632 0x9fbf 0x5dc 0x27dc 0x9f59 0x5dc 0x2985 0x9efe 0x5ea 0x2b2e 0x9ea7 0x611 0x2cd7 0x9e41 0x626 0x2e80 0x9dd2 0x63c 0x3029 0x9d64 0x640 0x31d3 0x9cfb 0x64d 0x337c 0x9c98 0x662 0x3525 0x9c3b 0x672 0x36ce 0x9bdf 0x676 0x3877 0x9b92 0x6a1 0x3a20 0x9b3e 0x6a4 0x3bc9 0x9aef 0x6a4 0x3d73 0x9aa3 0x6bc 0x3f1c 0x9a49 0x6c5 0x40c5 0x99d3 0x68d 0x426e 0x9943 0x623 0x4417 0x98bb 0x5b9 0x45c0 0x9849 0x573 0x476a 0x97f2 0x55f 0x4913 0x97a5 0x554 0x4abc 0x975e 0x546 0x4c65 0x9721 0x543 0x4e0e 0x96dd 0x52d 0x4fb7 0x96a2 0x52d 0x5160 0x966d 0x52d 0x530a 0x963a 0x53a 0x54b3 0x960b 0x550 0x565c 0x95de 0x559 0x5805 0x95ac 0x548 0x59ae 0x9581 0x55d 0x5b57 0x9557 0x55f 0x5d00 0x952c 0x55f 0x5eaa 0x9507 0x56b 0x6053 0x94e4 0x580 0x61fc 0x94c2 0x591 0x63a5 0x94a0 0x592 0x654e 0x947e 0x5a7 0x66f7 0x945c 0x5aa 0x68a1 0x9440 0x5b9 0x6a4a 0x9427 0x5ce 0x6bf3 0x940a 0x5d4 0x6d9c 0x93e8 0x5bf 0x6f45 0x93c6 0x5aa 0x70ee 0x93ac 0x5c0 0x7297 0x9384 0x5b1 0x7441 0x935a 0x59c 0x75ea 0x932f 0x587 0x7793 0x9305 0x578 0x793c 0x92da 0x575 0x7ae5 0x92b0 0x560 0x7c8e 0x928d 0x573 0x7e38 0x926b 0x578 0x7fe1 0x9249 0x578 0x818a 0x9227 0x581 0x8333 0x9201 0x591 0x84dc 0x91ce 0x591 0x8685 0x9192 0x591 0x882e 0x9156 0x57e 0x89d8 0x9121 0x597 0x8b81 0x90e0 0x59e 0x8d2a 0x9094 0x581 0x8ed3 0x9053 0x563 0x907c 0x9042 0x579 0x9225 0x9039 0x5a3 0x93ce 0x902a 0x5ce 0x9578 0x9013 0x5f8 0x9721 0x8fed 0x62d 0x98ca 0x8f7c 0x645 0x9a73 0x8e67 0x611 0x9c1c 0x8c93 0x626 0x9dc5 0x8a1c 0x68d 0x9f6f 0x8685 0x72a 0xa118 0x7f7d 0x144e 0xa2c1 0x78a0 0x203a 0xa46a 0x78a0 0x203a>;
				battery0_profile_t1_num = <0x64>;
				battery0_profile_t2 = <0x00 0xa956 0x834 0x1a9 0xa8a3 0x834 0x352 0xa80d 0x846 0x4fb 0xa787 0x84d 0x6a5 0xa70c 0x857 0x84e 0xa695 0x866 0x9f7 0xa61d 0x863 0xba0 0xa59d 0x84e 0xd49 0xa52e 0x875 0xef2 0xa4b9 0x86f 0x109c 0xa442 0x866 0x1245 0xa3ce 0x878 0x13ee 0xa360 0x898 0x1597 0xa2f1 0x899 0x1740 0xa282 0x8af 0x18e9 0xa214 0x8b1 0x1a92 0xa1a5 0x8c0 0x1c3c 0xa137 0x8ca 0x1de5 0xa0c8 0x8d2 0x1f8e 0xa05b 0x8e3 0x2137 0x9ff5 0x8e3 0x22e0 0x9f98 0x8f8 0x2489 0x9f41 0x91f 0x2632 0x9eec 0x958 0x27dc 0x9e8f 0x98d 0x2985 0x9e1f 0x9a5 0x2b2e 0x9d96 0x98f 0x2cd7 0x9d05 0x97a 0x2e80 0x9c85 0x979 0x3029 0x9c20 0x989 0x31d3 0x9bd1 0x9ab 0x337c 0x9b8d 0x9c4 0x3525 0x9b43 0x9be 0x36ce 0x9aee 0x9ab 0x3877 0x9a99 0x9ab 0x3a20 0x9a44 0x9ab 0x3bc9 0x99dc 0x97c 0x3d73 0x9964 0x930 0x3f1c 0x98e8 0x8e3 0x40c5 0x9874 0x8a3 0x426e 0x980f 0x865 0x4417 0x97ba 0x850 0x45c0 0x976c 0x83b 0x476a 0x972b 0x843 0x4913 0x96eb 0x842 0x4abc 0x96aa 0x834 0x4c65 0x9670 0x837 0x4e0e 0x963d 0x84d 0x4fb7 0x960a 0x84d 0x5160 0x95d7 0x84d 0x530a 0x95a9 0x85a 0x54b3 0x957f 0x866 0x565c 0x9554 0x86c 0x5805 0x952b 0x881 0x59ae 0x9509 0x896 0x5b57 0x94df 0x898 0x5d00 0x94bb 0x8a8 0x5eaa 0x9499 0x8b1 0x6053 0x947a 0x8c2 0x61fc 0x945e 0x8e3 0x63a5 0x943d 0x8e4 0x654e 0x9423 0x8f9 0x66f7 0x9402 0x8fc 0x68a1 0x93ec 0x919 0x6a4a 0x93d2 0x923 0x6bf3 0x93b6 0x915 0x6d9c 0x93a4 0x919 0x6f45 0x938a 0x92e 0x70ee 0x9379 0x943 0x7297 0x935a 0x936 0x7441 0x9338 0x92e 0x75ea 0x9316 0x938 0x7793 0x92f4 0x947 0x793c 0x92d1 0x947 0x7ae5 0x92a6 0x947 0x7c8e 0x928c 0x970 0x7e38 0x925e 0x98a 0x7fe1 0x922b 0x9ac 0x818a 0x91f5 0x9cd 0x8333 0x91b9 0x9dd 0x84dc 0x917e 0x9e2 0x8685 0x9142 0xa22 0x882e 0x90f7 0xa4e 0x89d8 0x90ab 0xa69 0x8b81 0x907a 0xa96 0x8d2a 0x9064 0xade 0x8ed3 0x9051 0xb33 0x907c 0x9038 0xb89 0x9225 0x901e 0xc33 0x93ce 0x8fef 0xd01 0x9578 0x8f3f 0xd9d 0x9721 0x8dd8 0xe5b 0x98ca 0x8bb3 0xf90 0x9a73 0x88cc 0x1171 0x9c1c 0x8494 0x14ae 0x9dc5 0x7b3a 0x23d8 0x9f6f 0x78d2 0x23dc 0xa118 0x78d2 0x23dc 0xa2c1 0x78d2 0x23dc 0xa46a 0x78d2 0x23dc>;
				battery0_profile_t2_num = <0x64>;
				battery0_profile_t3 = <0x00 0xa866 0xd02 0x1a9 0xa71a 0xcfe 0x352 0xa65b 0xdf2 0x4fb 0xa5c4 0xe69 0x6a5 0xa53c 0xe88 0x84e 0xa4bf 0xeac 0x9f7 0xa449 0xec4 0xba0 0xa3da 0xeef 0xd49 0xa364 0xef1 0xef2 0xa2f3 0xf01 0x109c 0xa285 0xf17 0x1245 0xa216 0xf2c 0x13ee 0xa1a8 0xf41 0x1597 0xa139 0xf55 0x1740 0xa0ca 0xf55 0x18e9 0xa05c 0xf55 0x1a92 0x9ff9 0xf64 0x1c3c 0x9fa0 0xf90 0x1de5 0x9f4f 0xfdf 0x1f8e 0x9efd 0x103a 0x2137 0x9e97 0x104f 0x22e0 0x9e0f 0x1024 0x2489 0x9d6f 0x100b 0x2632 0x9cd8 0x1004 0x27dc 0x9c54 0x1004 0x2985 0x9be3 0x100b 0x2b2e 0x9b80 0x101d 0x2cd7 0x9b34 0x101d 0x2e80 0x9af0 0x1046 0x3029 0x9a9e 0x102d 0x31d3 0x9a49 0x1010 0x337c 0x99e9 0xfde 0x3525 0x997a 0xf8f 0x36ce 0x990c 0xf51 0x3877 0x98a6 0xf26 0x3a20 0x9840 0xefc 0x3bc9 0x97e1 0xee1 0x3d73 0x978d 0xecc 0x3f1c 0x9743 0xec7 0x40c5 0x96ff 0xed8 0x426e 0x96bc 0xed8 0x4417 0x9680 0xed8 0x45c0 0x964c 0xefd 0x476a 0x9619 0xf19 0x4913 0x95e6 0xf2e 0x4abc 0x95b6 0xf4a 0x4c65 0x958b 0xf6e 0x4e0e 0x9561 0xf6e 0x4fb7 0x9536 0xf98 0x5160 0x950c 0xfb1 0x530a 0x94e7 0xfd4 0x54b3 0x94c1 0xff5 0x565c 0x9499 0x100a 0x5805 0x9477 0x1021 0x59ae 0x945e 0x104c 0x5b57 0x943d 0x1063 0x5d00 0x9421 0x1088 0x5eaa 0x9407 0x10b2 0x6053 0x93f1 0x10e5 0x61fc 0x93e0 0x1120 0x63a5 0x93cf 0x114b 0x654e 0x93be 0x1175 0x66f7 0x93ad 0x11b2 0x68a1 0x9396 0x11d5 0x6a4a 0x937d 0x11f5 0x6bf3 0x9363 0x1228 0x6d9c 0x9349 0x1268 0x6f45 0x9330 0x12a8 0x70ee 0x930e 0x12e8 0x7297 0x92e4 0x1327 0x7441 0x92c0 0x1383 0x75ea 0x9295 0x13d9 0x7793 0x9262 0x1426 0x793c 0x922e 0x1490 0x7ae5 0x91f3 0x14fa 0x7c8e 0x91b7 0x158d 0x7e38 0x917c 0x1611 0x7fe1 0x9136 0x169e 0x818a 0x90e6 0x172d 0x8333 0x909b 0x17c6 0x84dc 0x9072 0x1896 0x8685 0x9059 0x1995 0x882e 0x903f 0x1abb 0x89d8 0x901f 0x1c22 0x8b81 0x8ff9 0x1dcf 0x8d2a 0x8fa2 0x1fba 0x8ed3 0x8ecf 0x21ce 0x907c 0x8d2a 0x23ea 0x9225 0x8abd 0x27bc 0x93ce 0x8747 0x2d83 0x9578 0x8203 0x3212 0x9721 0x7a1c 0x3264 0x98ca 0x7a1c 0x3264 0x9a73 0x7a1c 0x3264 0x9c1c 0x7a1c 0x3264 0x9dc5 0x7a1c 0x3264 0x9f6f 0x7a1c 0x3264 0xa118 0x7a1c 0x3264 0xa2c1 0x7a1c 0x3264 0xa46a 0x7a1c 0x3264>;
				battery0_profile_t3_num = <0x64>;
				battery0_profile_t4 = <0x00 0xa6c2 0x1c0c 0x1a9 0xa5e5 0x1c08 0x352 0xa508 0x1cc8 0x4fb 0xa41a 0x1d88 0x6a5 0xa330 0x1e5a 0x84e 0xa262 0x1f66 0x9f7 0xa1bd 0x207b 0xba0 0xa13d 0x20fb 0xd49 0xa0c6 0x212a 0xef2 0xa055 0x2165 0x109c 0x9ff1 0x21be 0x1245 0x9f93 0x2205 0x13ee 0x9f32 0x2229 0x1597 0x9ec1 0x2274 0x1740 0x9e30 0x221f 0x18e9 0x9d91 0x21ef 0x1a92 0x9ce9 0x21d4 0x1c3c 0x9c4d 0x21ca 0x1de5 0x9bc2 0x21c2 0x1f8e 0x9b44 0x21a9 0x2137 0x9acd 0x217f 0x22e0 0x9a67 0x2194 0x2489 0x9a08 0x2175 0x2632 0x99ab 0x2166 0x27dc 0x994d 0x2152 0x2985 0x98f2 0x212e 0x2b2e 0x989d 0x211e 0x2cd7 0x9848 0x2133 0x2e80 0x97fa 0x20f6 0x3029 0x97ad 0x211c 0x31d3 0x9760 0x2127 0x337c 0x9718 0x2137 0x3525 0x96d6 0x2171 0x36ce 0x969b 0x21a0 0x3877 0x9668 0x21f5 0x3a20 0x962d 0x21e8 0x3bc9 0x95f8 0x2212 0x3d73 0x95c5 0x223a 0x3f1c 0x9592 0x223f 0x40c5 0x9561 0x2240 0x426e 0x9536 0x2295 0x4417 0x950c 0x22ea 0x45c0 0x94e1 0x22f6 0x476a 0x94bd 0x2330 0x4913 0x949b 0x239b 0x4abc 0x947b 0x2406 0x4c65 0x9462 0x244d 0x4e0e 0x9448 0x24b6 0x4fb7 0x942f 0x24f7 0x5160 0x941c 0x2547 0x530a 0x9406 0x25aa 0x54b3 0x93f0 0x2627 0x565c 0x93dd 0x26a5 0x5805 0x93c3 0x26e0 0x59ae 0x93aa 0x26f5 0x5b57 0x9390 0x276d 0x5d00 0x9371 0x280c 0x5eaa 0x9353 0x28b6 0x6053 0x9333 0x2936 0x61fc 0x930a 0x299c 0x63a5 0x92e8 0x2a84 0x654e 0x92b5 0x2b43 0x66f7 0x9282 0x2c15 0x68a1 0x924f 0x2cbd 0x6a4a 0x9217 0x2d45 0x6bf3 0x91dc 0x2de8 0x6d9c 0x919f 0x2edf 0x6f45 0x915b 0x3009 0x70ee 0x9117 0x3132 0x7297 0x90da 0x326d 0x7441 0x90a9 0x339a 0x75ea 0x9082 0x351b 0x7793 0x9060 0x36e5 0x793c 0x903c 0x3856 0x7ae5 0x9008 0x3a08 0x7c8e 0x8fa4 0x3bbb 0x7e38 0x8edb 0x3d1c 0x7fe1 0x8d6b 0x3e12 0x818a 0x8b3a 0x3f5d 0x8333 0x883e 0x40e1 0x84dc 0x8396 0x40e2 0x8685 0x79c2 0x40e2 0x882e 0x79c2 0x40e2 0x89d8 0x79c2 0x40e2 0x8b81 0x79c2 0x40e2 0x8d2a 0x79c2 0x40e2 0x8ed3 0x79c2 0x40e2 0x907c 0x79c2 0x40e2 0x9225 0x79c2 0x40e2 0x93ce 0x79c2 0x40e2 0x9578 0x79c2 0x40e2 0x9721 0x79c2 0x40e2 0x98ca 0x79c2 0x40e2 0x9a73 0x79c2 0x40e2 0x9c1c 0x79c2 0x40e2 0x9dc5 0x79c2 0x40e2 0x9f6f 0x79c2 0x40e2 0xa118 0x79c2 0x40e2 0xa2c1 0x79c2 0x40e2 0xa46a 0x79c2 0x40e2>;
				battery0_profile_t4_num = <0x64>;
				battery1_profile_t0 = <0x00 0xa942 0x5aa 0x1a4 0xa8ab 0x5aa 0x348 0xa821 0x5bb 0x4ec 0xa79b 0x5b6 0x690 0xa71c 0x5b3 0x834 0xa6a4 0x5be 0x9d8 0xa626 0x5aa 0xb7c 0xa5b1 0x5aa 0xd20 0xa53b 0x5bc 0xec4 0xa4c6 0x5b5 0x1068 0xa454 0x5b4 0x120c 0xa3e4 0x5bd 0x13b0 0xa370 0x5ac 0x1554 0xa302 0x5c1 0x16f8 0xa295 0x5c3 0x189c 0xa228 0x5c3 0x1a40 0xa1b6 0x5b8 0x1be4 0xa146 0x5b1 0x1d88 0xa0e0 0x5c3 0x1f2c 0xa073 0x5c3 0x20d0 0xa00e 0x5c3 0x2274 0x9fa9 0x5c3 0x2418 0x9f43 0x5cf 0x25bc 0x9edd 0x5d3 0x2760 0x9e7a 0x5c7 0x2904 0x9e1e 0x5dd 0x2aa8 0x9dc1 0x5f2 0x2c4c 0x9d65 0x5f5 0x2df0 0x9d09 0x5f5 0x2f94 0x9cac 0x5f5 0x3138 0x9c52 0x5f5 0x32dc 0x9bfe 0x5f5 0x3480 0x9baa 0x5f5 0x3624 0x9b5d 0x61a 0x37c8 0x9b12 0x627 0x396c 0x9ac6 0x632 0x3b10 0x9a7b 0x647 0x3cb4 0x9a2e 0x659 0x3e58 0x99da 0x659 0x3ffc 0x998e 0x66d 0x41a0 0x9942 0x682 0x4344 0x98e9 0x68b 0x44e8 0x9878 0x666 0x468c 0x97f4 0x607 0x4830 0x977f 0x5dd 0x49d4 0x9722 0x5b3 0x4b78 0x96d9 0x5aa 0x4d1c 0x969b 0x5b7 0x4ec0 0x9660 0x5ba 0x5064 0x9627 0x5aa 0x5208 0x95f5 0x5aa 0x53ac 0x95c2 0x5aa 0x5550 0x9597 0x5bc 0x56f4 0x9568 0x5b5 0x5898 0x9539 0x5aa 0x5a3c 0x9511 0x5aa 0x5be0 0x94f0 0x5ac 0x5d84 0x94ce 0x5c1 0x5f28 0x94a5 0x5c3 0x60cc 0x9481 0x5c3 0x6270 0x9463 0x5ce 0x6414 0x9448 0x5dc 0x65b8 0x9427 0x5df 0x675c 0x940e 0x5f4 0x6900 0x93ed 0x5e2 0x6aa4 0x93d1 0x5ec 0x6c48 0x93b8 0x5f5 0x6dec 0x939e 0x5fd 0x6f90 0x9384 0x60e 0x7134 0x9362 0x60e 0x72d8 0x931f 0x5cf 0x747c 0x92d5 0x5b2 0x7620 0x9299 0x5aa 0x77c4 0x926a 0x5b3 0x7968 0x9240 0x5c3 0x7b0c 0x9216 0x5c3 0x7cb0 0x91ec 0x5c3 0x7e54 0x91c2 0x5c3 0x7ff8 0x919e 0x5c3 0x819c 0x917c 0x5c3 0x8340 0x9158 0x5c9 0x84e4 0x912c 0x5da 0x8688 0x90f2 0x5c5 0x882c 0x90af 0x5c3 0x89d0 0x9078 0x5d2 0x8b74 0x9038 0x5d1 0x8d18 0x8fed 0x5bc 0x8ebc 0x8faa 0x5aa 0x9060 0x8f99 0x5aa 0x9204 0x8f88 0x5be 0x93a8 0x8f7e 0x5e3 0x954c 0x8f70 0x619 0x96f0 0x8f50 0x648 0x9894 0x8ef0 0x64d 0x9a38 0x8df4 0x60e 0x9bdc 0x8c1e 0x623 0x9d80 0x89b2 0x65a 0x9f24 0x8648 0x6e7 0xa0c8 0x802e 0x1071 0xa26c 0x730a 0xef1>;
				battery1_profile_t0_num = <0x64>;
				battery1_profile_t1 = <0x00 0xa8c0 0x73a 0x1a4 0xa829 0x73a 0x348 0xa7a6 0x75c 0x4ec 0xa728 0x75f 0x690 0xa6aa 0x741 0x834 0xa630 0x726 0x9d8 0xa5c2 0x739 0xb7c 0xa54d 0x724 0xd20 0xa4d7 0x70f 0xec4 0xa462 0x708 0x1068 0xa3f0 0x712 0x120c 0xa383 0x721 0x13b0 0xa316 0x721 0x1554 0xa2a8 0x721 0x16f8 0xa23b 0x70e 0x189c 0xa1ce 0x717 0x1a40 0xa161 0x716 0x1be4 0xa0f4 0x708 0x1d88 0xa088 0x70b 0x1f2c 0xa023 0x720 0x20d0 0x9fbe 0x721 0x2274 0x9f59 0x711 0x2418 0x9ef8 0x708 0x25bc 0x9e9b 0x719 0x2760 0x9e3c 0x736 0x2904 0x9dd8 0x722 0x2aa8 0x9d7b 0x74c 0x2c4c 0x9d18 0x753 0x2df0 0x9cb9 0x753 0x2f94 0x9c5c 0x753 0x3138 0x9c04 0x753 0x32dc 0x9bb9 0x756 0x3480 0x9b6d 0x780 0x3624 0x9b21 0x785 0x37c8 0x9adc 0x7a2 0x396c 0x9a90 0x7c2 0x3b10 0x9a3c 0x7c9 0x3cb4 0x99e9 0x7ba 0x3e58 0x999d 0x7cf 0x3ffc 0x9942 0x7bd 0x41a0 0x98e0 0x798 0x4344 0x9872 0x763 0x44e8 0x97fc 0x715 0x468c 0x978b 0x6b9 0x4830 0x972e 0x6a5 0x49d4 0x96e2 0x690 0x4b78 0x96a4 0x68b 0x4d1c 0x9669 0x68b 0x4ec0 0x9632 0x68b 0x5064 0x95ff 0x68b 0x5208 0x95cd 0x68b 0x53ac 0x959a 0x675 0x5550 0x956f 0x672 0x56f4 0x9545 0x672 0x5898 0x951f 0x67c 0x5a3c 0x94fd 0x691 0x5be0 0x94dc 0x6a4 0x5d84 0x94ba 0x6a4 0x5f28 0x9498 0x6a4 0x60cc 0x9477 0x6a4 0x6270 0x9459 0x6af 0x6414 0x943e 0x6bd 0x65b8 0x941d 0x6bd 0x675c 0x9404 0x6bd 0x6900 0x93eb 0x6d1 0x6aa4 0x93d1 0x6d6 0x6c48 0x93b8 0x6d6 0x6dec 0x939e 0x6ee 0x6f90 0x9385 0x721 0x7134 0x936c 0x721 0x72d8 0x934a 0x70c 0x747c 0x9322 0x6f7 0x7620 0x92fd 0x6e2 0x77c4 0x92d8 0x6cd 0x7968 0x92b0 0x6c7 0x7b0c 0x928e 0x6ee 0x7cb0 0x9264 0x6d9 0x7e54 0x9241 0x6d6 0x7ff8 0x9220 0x6e4 0x819c 0x91fa 0x6ef 0x8340 0x91cb 0x6ef 0x84e4 0x9190 0x6ed 0x8688 0x914c 0x6d8 0x882c 0x9118 0x6fc 0x89d0 0x90da 0x717 0x8b74 0x908a 0x721 0x8d18 0x903e 0x721 0x8ebc 0x9019 0x72a 0x9060 0x9010 0x769 0x9204 0x9000 0x76c 0x93a8 0x8fe9 0x7ac 0x954c 0x8fcb 0x800 0x96f0 0x8f89 0x86c 0x9894 0x8edf 0x8d7 0x9a38 0x8d54 0x898 0x9bdc 0x8b08 0x916 0x9d80 0x87dc 0x9e9 0x9f24 0x827d 0xc2f 0xa0c8 0x78dc 0x1de2 0xa26c 0x7724 0x1ac2>;
				battery1_profile_t1_num = <0x64>;
				battery1_profile_t2 = <0x00 0xa794 0xcfd 0x1a4 0xa6e4 0xcfd 0x348 0xa655 0xd1f 0x4ec 0xa5cf 0xd22 0x690 0xa54c 0xd16 0x834 0xa4d0 0xd20 0x9d8 0xa45a 0xd48 0xb7c 0xa3e5 0xd48 0xd20 0xa376 0xd48 0xec4 0xa309 0xd48 0x1068 0xa29c 0xd3e 0x120c 0xa22f 0xd2f 0x13b0 0xa1c2 0xd2f 0x1554 0xa154 0xd2f 0x16f8 0xa0e7 0xd2f 0x189c 0xa07a 0xd2f 0x1a40 0xa016 0xd45 0x1be4 0x9fb6 0xd61 0x1d88 0x9f54 0xd61 0x1f2c 0x9f00 0xd61 0x20d0 0x9eac 0xd89 0x2274 0x9e45 0xd83 0x2418 0x9dcd 0xd6e 0x25bc 0x9d50 0xd61 0x2760 0x9cdd 0xd5c 0x2904 0x9c70 0xd48 0x2aa8 0x9c13 0xd48 0x2c4c 0x9bc5 0xd7d 0x2df0 0x9b7f 0xd93 0x2f94 0x9b3c 0xdb0 0x3138 0x9af8 0xdde 0x32dc 0x9ab5 0xdde 0x3480 0x9a69 0xdde 0x3624 0x9a1d 0xdde 0x37c8 0x99d2 0xded 0x396c 0x997e 0xded 0x3b10 0x991f 0xdd8 0x3cb4 0x98b8 0xdb9 0x3e58 0x9842 0xd50 0x3ffc 0x97cd 0xd21 0x41a0 0x9764 0xcc9 0x4344 0x9708 0xc99 0x44e8 0x96ba 0xc92 0x468c 0x9677 0xc7c 0x4830 0x9634 0xc67 0x49d4 0x9601 0xca5 0x4b78 0x95ce 0xc91 0x4d1c 0x959c 0xca6 0x4ec0 0x956d 0xcba 0x5064 0x9543 0xca7 0x5208 0x9519 0xce3 0x53ac 0x94f8 0xcb9 0x5550 0x94cf 0xcd5 0x56f4 0x94aa 0xd0d 0x5898 0x9489 0xd25 0x5a3c 0x9467 0xd16 0x5be0 0x9446 0xd1b 0x5d84 0x942d 0xd5a 0x5f28 0x9414 0xd61 0x60cc 0x93fb 0xd52 0x6270 0x93e1 0xd72 0x6414 0x93cb 0xdac 0x65b8 0x93ba 0xdaf 0x675c 0x93a9 0xdc4 0x6900 0x9398 0xdc5 0x6aa4 0x9387 0xde5 0x6c48 0x9376 0xe0f 0x6dec 0x9366 0xe41 0x6f90 0x9353 0xe80 0x7134 0x933a 0xebf 0x72d8 0x9318 0xefe 0x747c 0x92f7 0xf3d 0x7620 0x92d0 0xf7c 0x77c4 0x92a6 0xfc4 0x7968 0x927c 0x1022 0x7b0c 0x9252 0x109e 0x7cb0 0x921f 0x10f2 0x7e54 0x91ed 0x1158 0x7ff8 0x91af 0x11c1 0x819c 0x916c 0x122a 0x8340 0x9129 0x129f 0x84e4 0x90e5 0x1330 0x8688 0x9099 0x13ae 0x882c 0x905d 0x1478 0x89d0 0x902e 0x1568 0x8b74 0x9008 0x167a 0x8d18 0x8fe4 0x1799 0x8ebc 0x8fb8 0x18b6 0x9060 0x8f7d 0x1a1b 0x9204 0x8f12 0x1b80 0x93a8 0x8e3e 0x1cc5 0x954c 0x8cd8 0x1e3c 0x96f0 0x8ab4 0x2048 0x9894 0x878d 0x2389 0x9a38 0x82dc 0x291d 0x9bdc 0x7468 0x12d9 0x9d80 0x7468 0x12d9 0x9f24 0x7468 0x12d9 0xa0c8 0x7468 0x12d9 0xa26c 0x7468 0x12d9>;
				battery1_profile_t2_num = <0x64>;
				battery1_profile_t3 = <0x00 0xa76c 0x19af 0x1a4 0xa6bc 0x19af 0x348 0xa620 0x199e 0x4ec 0xa58e 0x19d7 0x690 0xa502 0x1a25 0x834 0xa47e 0x1a3b 0x9d8 0xa400 0x1a11 0xb7c 0xa38b 0x19e7 0xd20 0xa315 0x19bd 0xec4 0xa2a0 0x19cb 0x1068 0xa22e 0x19cd 0x120c 0xa1c1 0x198b 0x13b0 0xa154 0x1919 0x1554 0xa0e6 0x1919 0x16f8 0xa079 0x193f 0x189c 0xa012 0x1969 0x1a40 0x9fb2 0x197d 0x1be4 0x9f58 0x1961 0x1d88 0x9f02 0x191c 0x1f2c 0x9e9d 0x1931 0x20d0 0x9e28 0x195a 0x2274 0x9da6 0x18f4 0x2418 0x9d23 0x1890 0x25bc 0x9caa 0x188c 0x2760 0x9c40 0x18b8 0x2904 0x9be4 0x1854 0x2aa8 0x9b90 0x18d2 0x2c4c 0x9b43 0x1890 0x2df0 0x9afd 0x18bb 0x2f94 0x9ab6 0x18da 0x3138 0x9a6a 0x18a1 0x32dc 0x9a1e 0x18b7 0x3480 0x99ca 0x18cc 0x3624 0x9976 0x18a9 0x37c8 0x991c 0x1871 0x396c 0x98c0 0x1847 0x3b10 0x9861 0x1818 0x3cb4 0x97fc 0x17c0 0x3e58 0x9797 0x17ea 0x3ffc 0x973a 0x1765 0x41a0 0x96ea 0x178c 0x4344 0x969a 0x175f 0x44e8 0x964f 0x1728 0x468c 0x9614 0x1794 0x4830 0x95d9 0x1740 0x49d4 0x95a7 0x1790 0x4b78 0x9574 0x17a2 0x4d1c 0x9547 0x1796 0x4ec0 0x951d 0x17a2 0x5064 0x94f3 0x17e2 0x5208 0x94c9 0x181e 0x53ac 0x94a8 0x17f4 0x5550 0x9486 0x1856 0x56f4 0x9464 0x1840 0x5898 0x9447 0x1823 0x5a3c 0x942d 0x1872 0x5be0 0x9415 0x18e2 0x5d84 0x9404 0x18a4 0x5f28 0x93fb 0x191d 0x60cc 0x93ec 0x1994 0x6270 0x93dc 0x19be 0x6414 0x93cd 0x19f7 0x65b8 0x93c4 0x1ac5 0x675c 0x93b3 0x1ad9 0x6900 0x939b 0x1b16 0x6aa4 0x9387 0x1be4 0x6c48 0x9372 0x1cb2 0x6dec 0x935c 0x1d5a 0x6f90 0x9348 0x1dfa 0x7134 0x9326 0x1e78 0x72d8 0x930d 0x1ef6 0x747c 0x92e6 0x1f85 0x7620 0x92bc 0x2018 0x77c4 0x9292 0x20b4 0x7968 0x9266 0x2166 0x7b0c 0x9234 0x2239 0x7cb0 0x9201 0x2320 0x7e54 0x91c8 0x2407 0x7ff8 0x9187 0x250a 0x819c 0x9148 0x2625 0x8340 0x910d 0x2745 0x84e4 0x90d2 0x285c 0x8688 0x9098 0x29ac 0x882c 0x905d 0x2afc 0x89d0 0x9028 0x2c6a 0x8b74 0x8ff1 0x2def 0x8d18 0x8fb6 0x2fc4 0x8ebc 0x8f78 0x3228 0x9060 0x8f24 0x349e 0x9204 0x8ea0 0x3638 0x93a8 0x8dc6 0x3787 0x954c 0x8c86 0x38f2 0x96f0 0x8aaf 0x3a91 0x9894 0x87f5 0x3c08 0x9a38 0x834f 0x36d5 0x9bdc 0x77d8 0x1ac2 0x9d80 0x77d8 0x1ac2 0x9f24 0x77d8 0x1ac2 0xa0c8 0x77d8 0x1ac2 0xa26c 0x77d8 0x1ac2>;
				battery1_profile_t3_num = <0x64>;
				battery1_profile_t4 = <0x00 0xa7da 0x2ff3 0x1a4 0xa700 0x2ff3 0x348 0xa640 0x307b 0x4ec 0xa597 0x3094 0x690 0xa4fb 0x300d 0x834 0xa468 0x2f58 0x9d8 0xa3e2 0x2f3b 0xb7c 0xa35b 0x2e7e 0xd20 0xa2dc 0x2e51 0xec4 0xa264 0x2dda 0x1068 0xa1ee 0x2d64 0x120c 0xa178 0x2d0d 0x13b0 0xa104 0x2c76 0x1554 0xa096 0x2bb9 0x16f8 0xa038 0x2bba 0x189c 0x9fdc 0x2b75 0x1a40 0x9f7b 0x2b2d 0x1be4 0x9f0e 0x2b03 0x1d88 0x9e90 0x2aca 0x1f2c 0x9e12 0x2a37 0x20d0 0x9d94 0x29e0 0x2274 0x9d16 0x297c 0x2418 0x9ca0 0x28ed 0x25bc 0x9c39 0x2898 0x2760 0x9bde 0x28b5 0x2904 0x9b8a 0x289e 0x2aa8 0x9b36 0x2835 0x2c4c 0x9ae2 0x2800 0x2df0 0x9a93 0x27fe 0x2f94 0x9a44 0x281d 0x3138 0x99f0 0x281b 0x32dc 0x999c 0x27a3 0x3480 0x9948 0x2779 0x3624 0x98ed 0x2762 0x37c8 0x9896 0x275b 0x396c 0x9842 0x2746 0x3b10 0x97eb 0x2716 0x3cb4 0x9790 0x26d9 0x3e58 0x973c 0x26af 0x3ffc 0x96f0 0x2671 0x41a0 0x96aa 0x2661 0x4344 0x9667 0x2678 0x44e8 0x9627 0x267d 0x468c 0x95ec 0x2653 0x4830 0x95b1 0x2692 0x49d4 0x957f 0x2693 0x4b78 0x9553 0x2672 0x4d1c 0x9529 0x266e 0x4ec0 0x94ff 0x2694 0x5064 0x94d7 0x26d3 0x5208 0x94b5 0x2712 0x53ac 0x949c 0x2751 0x5550 0x9483 0x276d 0x56f4 0x946f 0x2781 0x5898 0x945b 0x27b3 0x5a3c 0x9444 0x2812 0x5be0 0x9433 0x288d 0x5d84 0x9422 0x28e1 0x5f28 0x9411 0x2910 0x60cc 0x9400 0x2991 0x6270 0x93f0 0x2a24 0x6414 0x93df 0x2aa2 0x65b8 0x93ce 0x2b2d 0x675c 0x93bd 0x2c14 0x6900 0x93ac 0x2c86 0x6aa4 0x9395 0x2d10 0x6c48 0x937c 0x2dc8 0x6dec 0x9366 0x2eb2 0x6f90 0x9353 0x2fa7 0x7134 0x933a 0x3025 0x72d8 0x9318 0x3136 0x747c 0x92fe 0x3203 0x7620 0x92da 0x32cd 0x77c4 0x92b4 0x338d 0x7968 0x9290 0x3430 0x7b0c 0x9266 0x34c5 0x7cb0 0x923c 0x3582 0x7e54 0x920b 0x3687 0x7ff8 0x91d3 0x370c 0x819c 0x9198 0x3787 0x8340 0x915d 0x384a 0x84e4 0x9122 0x3918 0x8688 0x90de 0x39c0 0x882c 0x909b 0x3a55 0x89d0 0x9064 0x3ae8 0x8b74 0x9036 0x3bbd 0x8d18 0x900f 0x3cd5 0x8ebc 0x8fed 0x3dfe 0x9060 0x8fcc 0x3f39 0x9204 0x8f92 0x4100 0x93a8 0x8f17 0x42be 0x954c 0x8e02 0x44ef 0x96f0 0x8c2e 0x477d 0x9894 0x898b 0x467e 0x9a38 0x8587 0x3c8c 0x9bdc 0x7fd0 0x2ec7 0x9d80 0x7fd0 0x2ec7 0x9f24 0x7fd0 0x2ec7 0xa0c8 0x7fd0 0x2ec7 0xa26c 0x7fd0 0x2ec7>;
				battery1_profile_t4_num = <0x64>;
				compatible = "mediatek,bat_gm30";
				g_FG_PSEUDO100_T0 = <0x64>;
				g_FG_PSEUDO100_T1 = <0x64>;
				g_FG_PSEUDO100_T2 = <0x64>;
				g_FG_PSEUDO100_T3 = <0x64>;
				g_FG_PSEUDO100_T4 = <0x64>;
				phandle = <0x5d>;
			};

			fuelgauge {
				compatible = "mediatek, fuelgauge";
				enabled = <0x00>;
				phandle = <0x6f>;
			};

			kpd_volume_down {
				compatible = "mediatek, VOLUME_DOWN-eint";
				debounce = <0x7d00>;
				interrupt-parent = <0xffffffff>;
				interrupts = <0x5e 0x02 0x5e 0x00>;
				phandle = <0x69>;
				status = "okay";
			};

			kpd_volume_up {
				compatible = "mediatek, VOLUME_UP-eint";
				debounce = <0x7d00>;
				interrupt-parent = <0xffffffff>;
				interrupts = <0x14 0x02 0x14 0x00>;
				phandle = <0x68>;
				status = "okay";
			};

			led@0 {
				compatible = "mediatek,red";
				data = <0x01>;
				led_mode = <0x00>;
				phandle = <0x5e>;
				pwm_config = <0x00 0x00 0x00 0x00 0x00>;
			};

			led@1 {
				compatible = "mediatek,green";
				data = <0x01>;
				led_mode = <0x00>;
				phandle = <0x5f>;
				pwm_config = <0x00 0x00 0x00 0x00 0x00>;
			};

			led@2 {
				compatible = "mediatek,blue";
				data = <0x01>;
				led_mode = <0x00>;
				phandle = <0x60>;
				pwm_config = <0x00 0x00 0x00 0x00 0x00>;
			};

			led@3 {
				compatible = "mediatek,jogball-backlight";
				data = <0x01>;
				led_mode = <0x00>;
				phandle = <0x61>;
				pwm_config = <0x00 0x00 0x00 0x00 0x00>;
			};

			led@4 {
				compatible = "mediatek,keyboard-backlight";
				data = <0x01>;
				led_mode = <0x00>;
				phandle = <0x62>;
				pwm_config = <0x00 0x00 0x00 0x00 0x00>;
			};

			led@5 {
				compatible = "mediatek,button-backlight";
				data = <0x01>;
				led_mode = <0x00>;
				phandle = <0x63>;
				pwm_config = <0x00 0x00 0x00 0x00 0x00>;
			};

			led@6 {
				compatible = "mediatek,lcd-backlight";
				data = <0x01>;
				led_mode = <0x04>;
				phandle = <0x64>;
				pwm_config = <0x00 0x01 0x00 0x00 0x00>;
			};

			oppo_charger {
				compatible = "mediatek,oppo-charger";
				phandle = <0x6e>;
				pinctrl-0 = <0x04>;
				pinctrl-1 = <0x05>;
				pinctrl-2 = <0x06>;
				pinctrl-3 = <0x07>;
				pinctrl-4 = <0x08>;
				pinctrl-5 = <0x09>;
				pinctrl-names = "default\0charger_gpio_as_output_low\0charger_gpio_as_output_high\0ship_sleep\0ship_active\0shortc_active";
				qcom,batt_capacity_mah = <0x1004>;
				qcom,charger_hv_thr = <0x16a8>;
				qcom,charger_lv_thr = <0xd48>;
				qcom,chargerid_switch-gpio = <0xffffffff 0x61 0x00>;
				qcom,check_batt_full_by_sw;
				qcom,chg_ctrl_by_calling;
				qcom,chg_ctrl_by_camera;
				qcom,chg_ctrl_by_lcd;
				qcom,cold_bat_decidegc = <0x1e>;
				qcom,cold_vfloat_over_sw_limit = <0xf8c>;
				qcom,cold_vfloat_sw_limit = <0xf5a>;
				qcom,cool_bat_decidegc = <0x32>;
				qcom,cool_vfloat_over_sw_limit = <0x1126>;
				qcom,cool_vfloat_over_sw_limit_2nd = <0x112b>;
				qcom,cool_vfloat_sw_limit = <0x10ef>;
				qcom,default_iterm_ma = <0xc8>;
				qcom,default_iterm_ma_2nd = <0x12c>;
				qcom,default_normal_vfloat_over_sw_limit = <0x1126>;
				qcom,default_normal_vfloat_over_sw_limit_2nd = <0x112b>;
				qcom,default_normal_vfloat_sw_limit = <0x10ef>;
				qcom,default_temp_normal_fastchg_current_ma = <0x834>;
				qcom,default_temp_normal_vfloat_mv = <0x1121>;
				qcom,default_temp_normal_vfloat_mv_2nd = <0x1127>;
				qcom,external_gauge;
				qcom,ff1_exit_step_ma = <0x1e8>;
				qcom,ff1_normal_fastchg_ma = <0x440>;
				qcom,ff1_warm_exit_step_ma = <0x1a2>;
				qcom,ffc2_exit_step_ma = <0xb4>;
				qcom,ffc2_normal_fastchg_ma = <0x30c>;
				qcom,ffc2_temp_high_decidegc = <0x190>;
				qcom,ffc2_temp_low_decidegc = <0x78>;
				qcom,ffc2_temp_warm_decidegc = <0x15e>;
				qcom,ffc2_warm_exit_step_ma = <0xaa>;
				qcom,ffc2_warm_fastchg_ma = <0x348>;
				qcom,ffc_normal_vfloat_over_sw_limit = <0x1194>;
				qcom,ffc_normal_vfloat_sw_limit = <0x114e>;
				qcom,ffc_support;
				qcom,ffc_temp_normal_vfloat_mv = <0x1194>;
				qcom,hot_bat_decidegc = <0x212>;
				qcom,input_current_calling_ma = <0x5dc>;
				qcom,input_current_camera_ma = <0x4b0>;
				qcom,input_current_cdp_ma = <0x5dc>;
				qcom,input_current_charger_ma = <0x7d0>;
				qcom,input_current_led_ma = <0x4b0>;
				qcom,input_current_led_ma_forcmcc = <0x1f4>;
				qcom,input_current_led_ma_high = <0x4b0>;
				qcom,input_current_led_ma_normal = <0x4b0>;
				qcom,input_current_led_ma_warm = <0x4b0>;
				qcom,input_current_usb_ma = <0x1f4>;
				qcom,iterm_disabled = <0x00>;
				qcom,iterm_ma = <0xd2>;
				qcom,iterm_ma_2nd = <0x12c>;
				qcom,led_high_bat_decidegc = <0x17c>;
				qcom,led_warm_bat_decidegc = <0x15e>;
				qcom,little_cold_bat_decidegc = <0x00>;
				qcom,little_cold_vfloat_over_sw_limit = <0x1126>;
				qcom,little_cold_vfloat_over_sw_limit_2nd = <0x112b>;
				qcom,little_cold_vfloat_sw_limit = <0x10ef>;
				qcom,little_cool_bat_decidegc = <0x78>;
				qcom,little_cool_vfloat_over_sw_limit = <0x1126>;
				qcom,little_cool_vfloat_over_sw_limit_2nd = <0x112b>;
				qcom,little_cool_vfloat_sw_limit = <0x10ef>;
				qcom,max_chg_time_sec = <0x8ca0>;
				qcom,non_normal_vterm_hw_inc = <0x0a>;
				qcom,non_standard_fastchg_current_ma = <0x200>;
				qcom,non_standard_vfloat_mv = <0xfa0>;
				qcom,non_standard_vfloat_over_sw_limit = <0xf8c>;
				qcom,non_standard_vfloat_sw_limit = <0xf5a>;
				qcom,normal_bat_decidegc = <0xdc>;
				qcom,normal_vfloat_over_sw_limit = <0x1126>;
				qcom,normal_vfloat_over_sw_limit_2nd = <0x112b>;
				qcom,normal_vfloat_sw_limit = <0x10ef>;
				qcom,normal_vterm_hw_inc = <0x96>;
				qcom,recharge-mv = <0x64>;
				qcom,recharge-mv_2nd = <0x79>;
				qcom,removed_bat_decidegc = <0xbe>;
				qcom,ship-gpio = <0xffffffff 0x9b 0x00>;
				qcom,short_c_bat_cv_mv = <0x10ea>;
				qcom,short_c_bat_fastchg_current_ma = <0x200>;
				qcom,short_c_bat_vfloat_mv = <0xed8>;
				qcom,short_c_bat_vfloat_sw_limit = <0xea6>;
				qcom,shortc-gpio = <0xffffffff 0x4d 0x00>;
				qcom,sw_vfloat_over_protect_enable;
				qcom,temp_cold_fastchg_current_ma = <0x16c>;
				qcom,temp_cold_vfloat_mv = <0xf82>;
				qcom,temp_cool_fastchg_current_ma_high = <0x401>;
				qcom,temp_cool_fastchg_current_ma_low = <0x267>;
				qcom,temp_cool_vfloat_mv = <0x1112>;
				qcom,temp_cool_vfloat_mv_2nd = <0x1127>;
				qcom,temp_little_cold_fastchg_current_ma = <0x267>;
				qcom,temp_little_cold_fastchg_current_ma_high = <0x267>;
				qcom,temp_little_cold_fastchg_current_ma_low = <0x267>;
				qcom,temp_little_cold_vfloat_mv = <0x1112>;
				qcom,temp_little_cold_vfloat_mv_2nd = <0x1127>;
				qcom,temp_little_cool_fastchg_current_ma = <0x799>;
				qcom,temp_little_cool_vfloat_mv = <0x1112>;
				qcom,temp_little_cool_vfloat_mv_2nd = <0x1127>;
				qcom,temp_normal_fastchg_current_ma = <0xa69>;
				qcom,temp_normal_vfloat_mv = <0x1112>;
				qcom,temp_normal_vfloat_mv_2nd = <0x1127>;
				qcom,temp_normal_vfloat_mv_normalchg = <0x1112>;
				qcom,temp_warm_fastchg_current_ma = <0x401>;
				qcom,temp_warm_vfloat_mv = <0xff0>;
				qcom,vbatt_full_thr = <0x1130>;
				qcom,vbatt_hv_thr = <0x1194>;
				qcom,vbatt_num = <0x01>;
				qcom,vbatt_power_off = <0xce4>;
				qcom,vbatt_soc_1 = <0xd52>;
				qcom,vfloat_step_mv = <0x10>;
				qcom,warm_bat_decidegc = <0x1c2>;
				qcom,warm_vfloat_over_sw_limit = <0x1022>;
				qcom,warm_vfloat_sw_limit = <0xff0>;
			};

			oppo_devinfo {
				Hw,sub_hwid_1 = <0xffffffff 0x38 0x00>;
				compatible = "oppo, device_info";
				phandle = <0x6b>;
				pinctrl-0 = <0x01>;
				pinctrl-1 = <0x02>;
				pinctrl-2 = <0x03>;
				pinctrl-names = "default\0hw_sub_id_sleep\0hw_sub_id_active";
			};

			oppo_project {
				compatible = "oppo,oppo_project";
				phandle = <0x67>;
			};

			oppo_sensor {
				phandle = <0x6a>;
			};

			usb_c_pinctrl {
				compatible = "mediatek,usb_c_pinctrl";
				phandle = <0x66>;
			};

			vibrator@0 {
				compatible = "mediatek,vibrator";
				phandle = <0x65>;
				vib_limit = <0x00>;
				vib_timer = <0x1e>;
				vib_vol = <0x0b>;
			};

			vooc_ap_data {
				compatible = "mediatek, VOOC_AP_DATA-eint";
				interrupts = <0x1a 0x02 0x1a 0x00>;
				phandle = <0x6c>;
			};

			vooc_ap_data_new_function {
				compatible = "mediatek, VOOC_EINT_NEW_FUNCTION";
				phandle = <0x6d>;
			};
		};
	};

	fragment@20 {
		target = <0xffffffff>;

		__overlay__ {
			accdet-mic-mode = <0x01>;
			accdet-mic-vol = <0x07>;
			accdet-plugout-debounce = <0x01>;
			headset-eint-level-pol = <0x08>;
			headset-four-key-threshold = <0x00 0x3a 0x79 0xc0 0x190>;
			headset-mode-setting = <0x500 0x500 0x01 0x1f0 0x800 0x800 0x20 0x44>;
			headset-three-key-threshold = <0x00 0x50 0xdc 0x1ba>;
			headset-three-key-threshold-CDD = <0x00 0x79 0xc0 0x258>;
			status = "okay";
		};
	};

	fragment@21 {
		target = <0xffffffff>;

		__overlay__ {
			pinctrl-0 = <0x1c>;
			pinctrl-1 = <0x1d>;
			pinctrl-10 = <0x26>;
			pinctrl-11 = <0x27>;
			pinctrl-2 = <0x1e>;
			pinctrl-3 = <0x1f>;
			pinctrl-4 = <0x20>;
			pinctrl-5 = <0x21>;
			pinctrl-6 = <0x22>;
			pinctrl-7 = <0x23>;
			pinctrl-8 = <0x24>;
			pinctrl-9 = <0x25>;
			pinctrl-names = "aud_clk_mosi_off\0aud_clk_mosi_on\0aud_dat_mosi_off\0aud_dat_mosi_on\0aud_dat_miso_off\0aud_dat_miso_on\0extamp-pullhigh\0extamp-pulllow\0vow_dat_miso_off\0vow_dat_miso_on\0vow_clk_miso_off\0vow_clk_miso_on";
			status = "okay";
		};
	};

	fragment@22 {
		target = <0xffffffff>;

		__overlay__ {

			aud_clk_mosi_off {
				phandle = <0x1c>;

				pins_cmd0_dat {
					bias-disable;
					input-enable;
					pinmux = <0x8800>;
					slew-rate = <0x00>;
				};

				pins_cmd1_dat {
					bias-disable;
					input-enable;
					pinmux = <0x8900>;
					slew-rate = <0x00>;
				};
			};

			aud_clk_mosi_on {
				phandle = <0x1d>;

				pins_cmd0_dat {
					input-schmitt-enable;
					pinmux = <0x8801>;
				};

				pins_cmd1_dat {
					input-schmitt-enable;
					pinmux = <0x8901>;
				};
			};

			aud_dat_miso_off {
				phandle = <0x20>;

				pins_cmd0_dat {
					bias-disable;
					input-enable;
					pinmux = <0x8c00>;
					slew-rate = <0x00>;
				};

				pins_cmd1_dat {
					bias-disable;
					input-enable;
					pinmux = <0x8d00>;
					slew-rate = <0x00>;
				};

				pins_cmd2_dat {
					bias-disable;
					input-enable;
					pinmux = <0x8e00>;
					slew-rate = <0x00>;
				};

				pins_cmd3_dat {
					bias-disable;
					input-enable;
					pinmux = <0x8f00>;
					slew-rate = <0x00>;
				};
			};

			aud_dat_miso_on {
				phandle = <0x21>;

				pins_cmd0_dat {
					input-schmitt-enable;
					pinmux = <0x8c01>;
				};

				pins_cmd1_dat {
					input-schmitt-enable;
					pinmux = <0x8d01>;
				};

				pins_cmd2_dat {
					input-schmitt-enable;
					pinmux = <0x8e01>;
				};

				pins_cmd3_dat {
					input-schmitt-enable;
					pinmux = <0x8f01>;
				};
			};

			aud_dat_mosi_off {
				phandle = <0x1e>;

				pins_cmd0_dat {
					bias-disable;
					input-enable;
					pinmux = <0x8a00>;
					slew-rate = <0x00>;
				};

				pins_cmd1_dat {
					bias-pull-down;
					input-enable;
					pinmux = <0x8b00>;
					slew-rate = <0x00>;
				};
			};

			aud_dat_mosi_on {
				phandle = <0x1f>;

				pins_cmd0_dat {
					input-schmitt-enable;
					pinmux = <0x8a01>;
				};

				pins_cmd1_dat {
					input-schmitt-enable;
					pinmux = <0x8b01>;
				};
			};

			aud_extamp_pullhigh {
				phandle = <0x22>;

				pins_cmd_dat {
					output-high;
					pinmux = <0xa500>;
					slew-rate = <0x01>;
				};
			};

			aud_extamp_pulllow {
				phandle = <0x23>;

				pins_cmd_dat {
					output-low;
					pinmux = <0xa500>;
					slew-rate = <0x01>;
				};
			};

			vow_clk_miso_off {
				phandle = <0x26>;

				pins_cmd3_dat {
					pinmux = <0x8f00>;
				};
			};

			vow_clk_miso_on {
				phandle = <0x27>;

				pins_cmd3_dat {
					pinmux = <0x8f04>;
				};
			};

			vow_dat_miso_off {
				phandle = <0x24>;

				pins_cmd1_dat {
					pinmux = <0x8e00>;
				};
			};

			vow_dat_miso_on {
				phandle = <0x25>;

				pins_cmd1_dat {
					pinmux = <0x8e04>;
				};
			};
		};
	};

	fragment@23 {
		target = <0xffffffff>;

		__overlay__ {

			consys_default {
				phandle = <0x28>;
			};

			gpslna@0 {
				phandle = <0x29>;

				pins_cmd_dat {
					bias-disable;
					output-low;
					pinmux = <0x5c00>;
					slew-rate = <0x01>;
				};
			};

			gpslna@1 {
				phandle = <0x2a>;

				pins_cmd_dat {
					output-high;
					pinmux = <0x5c00>;
					slew-rate = <0x01>;
				};
			};

			gpslna@2 {
				phandle = <0x2b>;

				pins_cmd_dat {
					output-low;
					pinmux = <0x5c00>;
					slew-rate = <0x01>;
				};
			};
		};
	};

	fragment@24 {
		target = <0xffffffff>;

		__overlay__ {
			pinctrl-0 = <0x28>;
			pinctrl-1 = <0x29>;
			pinctrl-2 = <0x2a>;
			pinctrl-3 = <0x2b>;
			pinctrl-names = "default\0gps_lna_state_init\0gps_lna_state_oh\0gps_lna_state_ol";
			status = "okay";
		};
	};

	fragment@25 {
		target = <0xffffffff>;

		__overlay__ {
			pinctrl-0 = <0x2c>;
			pinctrl-1 = <0x2d>;
			pinctrl-2 = <0x2e>;
			pinctrl-3 = <0x2f>;
			pinctrl-4 = <0x30>;
			pinctrl-5 = <0x31>;
			pinctrl-6 = <0x32>;
			pinctrl-names = "uart0_gpio_default\0uart0_rx_set\0uart0_rx_clear\0uart0_tx_set\0uart0_tx_clear\0uart0_rx_gpio\0uart0_tx_gpio";
			status = "okay";
		};
	};

	fragment@26 {
		target = <0xffffffff>;

		__overlay__ {

			uart0_rx_clear@gpio95 {
				phandle = <0x2e>;

				pins_cmd_dat {
					output-high;
					pinmux = <0x5f00>;
					slew-rate = <0x01>;
				};
			};

			uart0_rx_gpio@gpio95 {
				phandle = <0x31>;

				pins_cmd_dat {
					bias-disable;
					input-enable;
					pinmux = <0x5f00>;
					slew-rate = <0x00>;
				};
			};

			uart0_rx_set@gpio95 {
				phandle = <0x2d>;

				pins_cmd_dat {
					pinmux = <0x5f01>;
				};
			};

			uart0_tx_clear@gpio96 {
				phandle = <0x30>;

				pins_cmd_dat {
					output-high;
					pinmux = <0x6000>;
					slew-rate = <0x01>;
				};
			};

			uart0_tx_gpio@gpio96 {
				phandle = <0x32>;

				pins_cmd_dat {
					bias-disable;
					input-enable;
					pinmux = <0x6000>;
					slew-rate = <0x00>;
				};
			};

			uart0_tx_set@gpio96 {
				phandle = <0x2f>;

				pins_cmd_dat {
					pinmux = <0x6001>;
				};
			};

			uart0gpiodefault {
				phandle = <0x2c>;
			};
		};
	};

	fragment@27 {
		target = <0xffffffff>;

		__overlay__ {
			pinctrl-0 = <0x33>;
			pinctrl-1 = <0x34>;
			pinctrl-names = "irtx_gpio_led_default\0irtx_gpio_led_set";
			status = "okay";
		};
	};

	fragment@28 {
		target = <0xffffffff>;

		__overlay__ {

			irtx_gpio_led_def@gpio90 {
				phandle = <0x33>;

				pins_cmd_dat {
					bias-disable;
					input-schmitt-enable = <0x00>;
					output-low;
					pinmux = <0x5a00>;
					slew-rate = <0x01>;
				};
			};

			irtx_gpio_led_set@gpio90 {
				phandle = <0x34>;

				pins_cmd_dat {
					output-high;
					pinmux = <0x5a01>;
					slew-rate = <0x01>;
				};
			};
		};
	};

	fragment@29 {
		target = <0xffffffff>;

		__overlay__ {
			mt6370,intr_gpio = <0xffffffff 0x0a 0x00>;
			mt6370,intr_gpio_num = <0x0a>;
		};
	};

	fragment@3 {
		target = <0xffffffff>;

		__overlay__ {
			#address-cells = <0x01>;
			#size-cells = <0x00>;
			status = "okay";

			finger_spi@0 {
				compatible = "mediatek,fingerspi-fp";
				netlink-event = <0x1e>;
				reg = <0x00>;
				spi-id = <0x00>;
				spi-irq = <0x16>;
				spi-max-frequency = <0x7a1200>;
				spi-reg = <0x1100a000>;
				status = "okay";
			};
		};
	};

	fragment@30 {
		target = <0xffffffff>;

		__overlay__ {
			keypad,volume-down = <0xffffffff 0x5e 0x00>;
			keypad,volume-up = <0xffffffff 0x14 0x00>;
			pinctrl-0 = <0x35>;
			pinctrl-1 = <0x36>;
			pinctrl-names = "volume_up_as_int\0volume_down_as_int";
			status = "okay";
		};
	};

	fragment@31 {
		target = <0xffffffff>;

		__overlay__ {

			volume_down@0 {
				phandle = <0x36>;

				pins_cmd_dat {
					bias-pull-up = <0x00>;
					input-enable;
					pinmux = <0x5e00>;
					slew-rate = <0x00>;
				};
			};

			volume_up@0 {
				phandle = <0x35>;

				pins_cmd_dat {
					bias-pull-up = <0x00>;
					input-enable;
					pinmux = <0x1400>;
					slew-rate = <0x00>;
				};
			};
		};
	};

	fragment@32 {
		target = <0xffffffff>;

		__overlay__ {
			pinctrl-0 = <0x37>;
			pinctrl-1 = <0x38>;
			pinctrl-names = "msdc1_on\0msdc1_off";
			status = "okay";
		};
	};

	fragment@33 {
		target = <0xffffffff>;

		__overlay__ {

			sd0@0 {
				phandle = <0x37>;

				pins_cmd_dat {
					output-high;
					pinmux = <0x5a00>;
					slew-rate = <0x01>;
				};
			};

			sd0@1 {
				phandle = <0x38>;

				pins_cmd_dat {
					output-low;
					pinmux = <0x5a00>;
					slew-rate = <0x01>;
				};
			};
		};
	};

	fragment@34 {
		target = <0xffffffff>;

		__overlay__ {
			algorithm_name = "SwitchCharging";
			chg1_ta_ac_charger_current = <0x1e8480>;
			chg2_ta_ac_charger_current = <0x1e8480>;
		};
	};

	fragment@35 {
		target = <0xffffffff>;

		__overlay__ {

			charger_gpio_as_output_high {
				phandle = <0x06>;

				pins_cmd_dat {
					output-high;
					pinmux = <0x9700>;
					slew-rate = <0x01>;
				};
			};

			charger_gpio_as_output_low {
				phandle = <0x05>;

				pins_cmd_dat {
					output-low;
					pinmux = <0x9700>;
					slew-rate = <0x01>;
				};
			};

			eint0default {
				phandle = <0x04>;
			};

			ship_active {
				phandle = <0x08>;

				pins_cmd_dat {
					output-high;
					pinmux = <0x9800>;
					slew-rate = <0x01>;
				};
			};

			ship_sleep {
				phandle = <0x07>;

				pins_cmd_dat {
					output-low;
					pinmux = <0x9800>;
					slew-rate = <0x01>;
				};
			};

			shortc_active {
				phandle = <0x09>;

				pins_cmd_dat {
					bias-pull-up;
					input-enable;
					pinmux = <0x1700>;
					slew-rate = <0x00>;
				};
			};
		};
	};

	fragment@36 {
		target = <0xffffffff>;

		__overlay__ {

			charging_clock_active {
				phandle = <0x86>;

				pins_cmd_dat {
					bias-pull-up = <0x00>;
					pinmux = <0xa00>;
					slew-rate = <0x00>;
				};
			};

			charging_clock_sleep {
				phandle = <0x87>;

				pins_cmd_dat {
					bias-pull-down = <0x00>;
					pinmux = <0xa00>;
					slew-rate = <0x00>;
				};
			};

			charging_data_active {
				phandle = <0x88>;

				pins_cmd_dat {
					bias-pull-up = <0x00>;
					pinmux = <0xa00>;
					slew-rate = <0x00>;
				};
			};

			charging_data_sleep {
				phandle = <0x89>;

				pins_cmd_dat {
					bias-pull-down = <0x00>;
					pinmux = <0xa00>;
					slew-rate = <0x00>;
				};
			};

			charging_reset_active {
				phandle = <0x8a>;

				pins_cmd_dat {
					output-high;
					pinmux = <0xa000>;
					slew-rate = <0x01>;
				};
			};

			charging_reset_sleep {
				phandle = <0x8b>;

				pins_cmd_dat {
					output-low;
					pinmux = <0xa000>;
					slew-rate = <0x01>;
				};
			};

			charging_switch1_active {
				phandle = <0x84>;

				pins_cmd_dat {
					output-high;
					pinmux = <0xa600>;
					slew-rate = <0x01>;
				};
			};

			charging_switch1_sleep {
				phandle = <0x85>;

				pins_cmd_dat {
					output-low;
					pinmux = <0xa600>;
					slew-rate = <0x01>;
				};
			};
		};
	};

	fragment@37 {
		target = <0xffffffff>;

		__overlay__ {

			active@id1 {
				phandle = <0x03>;

				pins_cmd_dat {
					bias-pull-up = <0x00>;
					input-enable;
					pinmux = <0x3800>;
					slew-rate = <0x00>;
				};
			};

			default@hw_sub_id {
				phandle = <0x01>;
			};

			sleep@id1 {
				phandle = <0x02>;

				pins_cmd_dat {
					bias-pull-down = <0x00>;
					input-enable;
					pinmux = <0x3800>;
					slew-rate = <0x00>;
				};
			};
		};
	};

	fragment@38 {
		target = <0xffffffff>;

		__overlay__ {
			pinctrl-0 = <0x39>;
			pinctrl-1 = <0x3a>;
			pinctrl-names = "i2c-state\0output-low-state";
		};
	};

	fragment@39 {
		target = <0xffffffff>;

		__overlay__ {

			i2c6_sda_i2c_state {
				phandle = <0x39>;

				pins_cmd_dat {
					bias-disable;
					pinmux = <0xc03>;
					slew-rate = <0x00>;
				};
			};

			i2c6_sda_output_low_state {
				phandle = <0x3a>;

				pins_cmd_dat {
					output-low;
					pinmux = <0xc00>;
					slew-rate = <0x01>;
				};
			};
		};
	};

	fragment@4 {
		target = <0xffffffff>;

		__overlay__ {
			pinctrl-0 = <0x0a>;
			pinctrl-1 = <0x0b>;
			pinctrl-2 = <0x0c>;
			pinctrl-3 = <0x0d>;
			pinctrl-names = "default\0rst-low\0rst-high\0irq-init";
			status = "okay";
		};
	};

	fragment@40 {
		target = <0xffffffff>;

		__overlay__ {

			adc_channel@ {
				compatible = "mediatek,adc_channel";
				mediatek,adc_fdd_rf_params_dynamic_custom_ch = <0x02>;
				mediatek,temperature0 = <0x00>;
				mediatek,temperature1 = <0x01>;
				status = "okay";
			};
		};
	};

	fragment@41 {
		target = <0xffffffff>;

		__overlay__ {
			mediatek,clkbuf-config = <0x02 0x01 0x01 0x02 0x00 0x00 0x01>;
			mediatek,clkbuf-driving-current = <0xffffffff 0xffffffff 0xffffffff 0xffffffff 0xffffffff 0xffffffff 0xffffffff>;
			mediatek,clkbuf-quantity = <0x07>;
			status = "okay";
		};
	};

	fragment@42 {
		target = <0xffffffff>;

		__overlay__ {
			#address-cells = <0x01>;
			#size-cells = <0x00>;
			clock-frequency = <0x61a80>;
			mediatek,use-open-drain;

			cap_touch@5d {
				compatible = "mediatek,cap_touch";
				phandle = <0x8c>;
				reg = <0x5d>;
				status = "okay";
			};
		};
	};

	fragment@43 {
		target = <0xffffffff>;

		__overlay__ {
			#address-cells = <0x01>;
			#size-cells = <0x00>;
			clock-frequency = <0x61a80>;
			mediatek,use-open-drain;

			alsps@51 {
				compatible = "mediatek,alsps";
				interrupt-parent = <0xffffffff>;
				interrupts = <0x06 0x08 0x06 0x00>;
				phandle = <0x8e>;
				reg = <0x51>;
				status = "okay";
			};

			barometer@77 {
				compatible = "mediatek,barometer";
				phandle = <0x8f>;
				reg = <0x77>;
				status = "okay";
			};

			msensor@0c {
				compatible = "mediatek,msensor";
				phandle = <0x8d>;
				reg = <0x0c>;
				status = "okay";
			};
		};
	};

	fragment@44 {
		target = <0xffffffff>;

		__overlay__ {
			#address-cells = <0x01>;
			#size-cells = <0x00>;
			clock-frequency = <0x61a80>;
			mediatek,use-open-drain;

			camera_main@1a {
				compatible = "mediatek,camera_main";
				phandle = <0x90>;
				reg = <0x1a>;
				status = "okay";
			};

			camera_main_af@72 {
				compatible = "mediatek,camera_main_af";
				phandle = <0x91>;
				reg = <0x72>;
				status = "okay";
			};

			camera_main_eeprom@50 {
				compatible = "mediatek,camera_main_eeprom";
				phandle = <0x92>;
				reg = <0x50>;
				status = "okay";
			};

			ccu_sensor_i2c_2_hw@33 {
				compatible = "mediatek,ccu_sensor_i2c_2_hw";
				phandle = <0x93>;
				reg = <0x33>;
				status = "okay";
			};
		};
	};

	fragment@45 {
		target = <0xffffffff>;

		__overlay__ {
			#address-cells = <0x01>;
			#size-cells = <0x00>;
			clock-frequency = <0x61a80>;
			mediatek,use-open-drain;

			nfc@08 {
				compatible = "mediatek,nfc";
				phandle = <0x94>;
				reg = <0x08>;
				status = "okay";
			};
		};
	};

	fragment@46 {
		target = <0xffffffff>;

		__overlay__ {
			#address-cells = <0x01>;
			#size-cells = <0x00>;
			clock-frequency = <0x61a80>;
			mediatek,use-open-drain;

			camera_main_two@10 {
				compatible = "mediatek,camera_main_two";
				phandle = <0x95>;
				reg = <0x10>;
				status = "okay";
			};

			camera_main_two_af@72 {
				compatible = "mediatek,camera_main_two_af";
				phandle = <0x96>;
				reg = <0x72>;
				status = "okay";
			};

			camera_main_two_eeprom@51 {
				compatible = "mediatek,camera_main_two_eeprom";
				phandle = <0x97>;
				reg = <0x51>;
				status = "okay";
			};

			camera_sub@35 {
				compatible = "mediatek,camera_sub";
				phandle = <0x98>;
				reg = <0x35>;
				status = "okay";
			};

			camera_sub_eeprom@54 {
				compatible = "mediatek,camera_sub_eeprom";
				phandle = <0x99>;
				reg = <0x54>;
				status = "okay";
			};

			ccu_sensor_i2c_4_hw@36 {
				compatible = "mediatek,ccu_sensor_i2c_4_hw";
				phandle = <0x9a>;
				reg = <0x36>;
				status = "okay";
			};
		};
	};

	fragment@47 {
		target = <0xffffffff>;

		__overlay__ {
			#address-cells = <0x01>;
			#size-cells = <0x00>;
			clock-frequency = <0x33e140>;
			mediatek,use-push-pull;

			subpmic_pmu@34 {
				compatible = "mediatek,subpmic_pmu";
				phandle = <0x9c>;
				reg = <0x34>;
				status = "okay";
			};

			usb_type_c@4e {
				compatible = "mediatek,usb_type_c";
				phandle = <0x9b>;
				reg = <0x4e>;
				status = "okay";
			};
		};
	};

	fragment@48 {
		target = <0xffffffff>;

		__overlay__ {
			#address-cells = <0x01>;
			#size-cells = <0x00>;
			clock-frequency = <0x61a80>;
			mediatek,use-open-drain;

			slave_charger@4b {
				compatible = "mediatek,slave_charger";
				phandle = <0x9e>;
				reg = <0x4b>;
				status = "okay";
			};

			speaker_amp@34 {
				compatible = "mediatek,speaker_amp";
				phandle = <0x9d>;
				reg = <0x34>;
				status = "okay";
			};
		};
	};

	fragment@49 {
		target = <0xffffffff>;

		__overlay__ {
			#address-cells = <0x01>;
			#size-cells = <0x00>;
			clock-frequency = <0x61a80>;
			mediatek,use-open-drain;
		};
	};

	fragment@5 {
		target = <0xffffffff>;

		__overlay__ {

			fp_eint@8 {
				phandle = <0x0d>;

				pins_cmd_dat {
					bias-disable;
					pinmux = <0x1600>;
					slew-rate = <0x00>;
				};
			};

			silfpdefault {
				phandle = <0x0a>;
			};

			state_reset_high {
				phandle = <0x0c>;

				pins_cmd_dat {
					output-high;
					pinmux = <0x9e00>;
					slew-rate = <0x01>;
				};
			};

			state_reset_low {
				phandle = <0x0b>;

				pins_cmd_dat {
					output-low;
					pinmux = <0x9e00>;
					slew-rate = <0x01>;
				};
			};
		};
	};

	fragment@50 {
		target = <0xffffffff>;

		__overlay__ {
			#address-cells = <0x01>;
			#size-cells = <0x00>;
			clock-frequency = <0x61a80>;
			mediatek,use-open-drain;
		};
	};

	fragment@51 {
		target = <0xffffffff>;

		__overlay__ {
			#address-cells = <0x01>;
			#size-cells = <0x00>;
			clock-frequency = <0x61a80>;
			mediatek,use-open-drain;
		};
	};

	fragment@52 {
		target = <0xffffffff>;

		__overlay__ {
			#address-cells = <0x01>;
			#size-cells = <0x00>;
			clock-frequency = <0x61a80>;
			mediatek,use-open-drain;
		};
	};

	fragment@53 {
		target = <0xffffffff>;

		__overlay__ {
			#address-cells = <0x01>;
			#size-cells = <0x00>;
			clock-frequency = <0x61a80>;
			mediatek,use-open-drain;
		};
	};

	fragment@54 {
		target = <0xffffffff>;

		__overlay__ {
			GPIO_FDD_BAND_SUPPORT_DETECT_1ST_PIN = <0xffffffff 0x4f 0x00>;
			GPIO_FDD_BAND_SUPPORT_DETECT_2ND_PIN = <0xffffffff 0x50 0x00>;
			GPIO_FDD_BAND_SUPPORT_DETECT_3RD_PIN = <0xffffffff 0x35 0x00>;
			GPIO_SIM1_HOT_PLUG = <0xffffffff 0x2f 0x00>;
			GPIO_SIM1_SCLK = <0xffffffff 0x26 0x00>;
			GPIO_SIM1_SIO = <0xffffffff 0x28 0x00>;
			GPIO_SIM1_SRST = <0xffffffff 0x27 0x00>;
			GPIO_SIM2_HOT_PLUG = <0xffffffff 0x2e 0x00>;
			GPIO_SIM2_SCLK = <0xffffffff 0x25 0x00>;
			GPIO_SIM2_SIO = <0xffffffff 0x23 0x00>;
			GPIO_SIM2_SRST = <0xffffffff 0x24 0x00>;
		};
	};

	fragment@55 {
		target = <0xffffffff>;

		__overlay__ {
			gpio_init_default = <0x00 0x00 0x00 0x00 0x01 0x01 0x01 0x01 0x00 0x00 0x00 0x01 0x01 0x01 0x02 0x00 0x00 0x00 0x00 0x00 0x01 0x03 0x00 0x00 0x00 0x01 0x01 0x01 0x04 0x00 0x00 0x00 0x01 0x01 0x00 0x05 0x00 0x00 0x00 0x01 0x01 0x00 0x06 0x00 0x00 0x00 0x01 0x01 0x00 0x07 0x00 0x00 0x00 0x01 0x00 0x00 0x08 0x07 0x00 0x00 0x00 0x00 0x00 0x09 0x00 0x00 0x00 0x01 0x01 0x00 0x0a 0x00 0x00 0x00 0x01 0x01 0x00 0x0b 0x00 0x00 0x00 0x01 0x00 0x00 0x0c 0x00 0x00 0x00 0x01 0x00 0x00 0x0d 0x02 0x00 0x00 0x01 0x01 0x00 0x0e 0x02 0x01 0x00 0x01 0x01 0x00 0x0f 0x02 0x01 0x00 0x00 0x00 0x00 0x10 0x02 0x01 0x00 0x01 0x01 0x00 0x11 0x00 0x00 0x00 0x01 0x00 0x00 0x12 0x00 0x00 0x00 0x01 0x00 0x00 0x13 0x00 0x00 0x00 0x01 0x00 0x00 0x14 0x00 0x00 0x00 0x01 0x00 0x00 0x15 0x00 0x00 0x00 0x01 0x00 0x00 0x16 0x00 0x00 0x00 0x01 0x00 0x00 0x17 0x00 0x00 0x00 0x01 0x00 0x00 0x18 0x05 0x00 0x00 0x00 0x00 0x00 0x19 0x05 0x01 0x00 0x00 0x00 0x00 0x1a 0x05 0x00 0x00 0x00 0x00 0x00 0x1b 0x05 0x01 0x00 0x00 0x00 0x00 0x1c 0x05 0x01 0x00 0x00 0x00 0x00 0x1d 0x01 0x01 0x00 0x00 0x00 0x00 0x1e 0x01 0x00 0x00 0x01 0x01 0x00 0x1f 0x01 0x00 0x00 0x01 0x01 0x00 0x20 0x01 0x00 0x00 0x01 0x01 0x00 0x21 0x01 0x00 0x00 0x01 0x01 0x00 0x22 0x01 0x00 0x00 0x01 0x01 0x00 0x23 0x01 0x00 0x00 0x01 0x01 0x00 0x24 0x01 0x01 0x00 0x00 0x00 0x00 0x25 0x01 0x01 0x00 0x00 0x00 0x00 0x26 0x01 0x01 0x00 0x00 0x00 0x00 0x27 0x01 0x01 0x00 0x00 0x00 0x00 0x28 0x01 0x00 0x00 0x01 0x01 0x00 0x29 0x00 0x00 0x00 0x01 0x01 0x00 0x2a 0x00 0x01 0x00 0x00 0x00 0x00 0x2b 0x01 0x01 0x00 0x00 0x00 0x00 0x2c 0x01 0x00 0x00 0x01 0x00 0x00 0x2d 0x00 0x01 0x00 0x00 0x00 0x00 0x2e 0x01 0x00 0x00 0x01 0x01 0x00 0x2f 0x01 0x00 0x00 0x01 0x01 0x00 0x30 0x01 0x00 0x00 0x01 0x01 0x00 0x31 0x01 0x00 0x00 0x01 0x01 0x00 0x32 0x01 0x00 0x00 0x01 0x01 0x00 0x33 0x00 0x00 0x00 0x01 0x00 0x00 0x34 0x00 0x00 0x00 0x01 0x00 0x00 0x35 0x00 0x00 0x00 0x00 0x00 0x00 0x36 0x01 0x01 0x00 0x01 0x00 0x00 0x37 0x01 0x01 0x00 0x01 0x00 0x00 0x38 0x00 0x00 0x00 0x00 0x00 0x00 0x39 0x01 0x01 0x00 0x01 0x00 0x00 0x3a 0x00 0x00 0x00 0x01 0x00 0x00 0x3b 0x01 0x00 0x00 0x01 0x00 0x00 0x3c 0x01 0x00 0x00 0x01 0x00 0x00 0x3d 0x01 0x00 0x00 0x01 0x00 0x00 0x3e 0x01 0x00 0x00 0x01 0x00 0x00 0x3f 0x01 0x00 0x00 0x01 0x00 0x00 0x40 0x01 0x00 0x00 0x01 0x00 0x00 0x41 0x00 0x00 0x00 0x01 0x00 0x00 0x42 0x00 0x00 0x00 0x01 0x00 0x00 0x43 0x00 0x00 0x00 0x01 0x00 0x00 0x44 0x00 0x00 0x00 0x01 0x00 0x00 0x45 0x01 0x01 0x00 0x01 0x00 0x00 0x46 0x01 0x01 0x00 0x01 0x00 0x00 0x47 0x01 0x01 0x00 0x01 0x00 0x00 0x48 0x00 0x00 0x00 0x01 0x00 0x00 0x49 0x01 0x01 0x00 0x01 0x00 0x00 0x4a 0x01 0x01 0x00 0x01 0x00 0x00 0x4b 0x01 0x01 0x00 0x01 0x00 0x00 0x4c 0x01 0x01 0x00 0x01 0x00 0x00 0x4d 0x01 0x01 0x00 0x01 0x00 0x00 0x4e 0x01 0x01 0x00 0x01 0x00 0x00 0x4f 0x00 0x00 0x00 0x00 0x00 0x00 0x50 0x00 0x00 0x00 0x00 0x00 0x00 0x51 0x01 0x00 0x00 0x01 0x01 0x00 0x52 0x01 0x00 0x00 0x01 0x01 0x00 0x53 0x01 0x00 0x00 0x01 0x01 0x00 0x54 0x01 0x00 0x00 0x01 0x01 0x00 0x55 0x01 0x00 0x00 0x01 0x00 0x00 0x56 0x01 0x01 0x00 0x00 0x00 0x00 0x57 0x01 0x01 0x00 0x00 0x00 0x00 0x58 0x01 0x01 0x00 0x00 0x00 0x00 0x59 0x00 0x00 0x00 0x01 0x00 0x00 0x5a 0x00 0x00 0x00 0x01 0x00 0x00 0x5b 0x00 0x00 0x00 0x01 0x00 0x00 0x5c 0x00 0x01 0x00 0x01 0x00 0x00 0x5d 0x01 0x00 0x00 0x01 0x01 0x00 0x5e 0x01 0x00 0x00 0x01 0x01 0x00 0x5f 0x01 0x00 0x00 0x01 0x01 0x00 0x60 0x01 0x01 0x00 0x00 0x00 0x00 0x61 0x00 0x01 0x00 0x00 0x00 0x00 0x62 0x00 0x01 0x00 0x00 0x00 0x00 0x63 0x01 0x01 0x00 0x00 0x00 0x00 0x64 0x01 0x01 0x00 0x00 0x00 0x00 0x65 0x00 0x01 0x01 0x00 0x00 0x00 0x66 0x00 0x01 0x01 0x00 0x00 0x00 0x67 0x01 0x01 0x00 0x00 0x00 0x00 0x68 0x01 0x00 0x00 0x00 0x00 0x00 0x69 0x01 0x01 0x00 0x00 0x00 0x00 0x6a 0x01 0x00 0x00 0x00 0x00 0x00 0x6b 0x00 0x01 0x00 0x00 0x00 0x00 0x6c 0x01 0x01 0x00 0x00 0x00 0x00 0x6d 0x00 0x01 0x01 0x00 0x00 0x00 0x6e 0x00 0x00 0x00 0x01 0x00 0x00 0x6f 0x00 0x00 0x00 0x01 0x00 0x00 0x70 0x00 0x00 0x00 0x01 0x00 0x00 0x71 0x00 0x00 0x00 0x01 0x00 0x00 0x72 0x00 0x00 0x00 0x01 0x00 0x00 0x73 0x00 0x00 0x00 0x01 0x00 0x00 0x74 0x00 0x00 0x00 0x01 0x00 0x00 0x75 0x00 0x00 0x00 0x01 0x00 0x00 0x76 0x00 0x00 0x00 0x01 0x00 0x00 0x77 0x00 0x00 0x00 0x01 0x00 0x00 0x78 0x00 0x00 0x00 0x01 0x00 0x00 0x79 0x00 0x00 0x00 0x01 0x00 0x00 0x7a 0x01 0x00 0x00 0x01 0x01 0x00 0x7b 0x01 0x00 0x00 0x01 0x01 0x00 0x7c 0x01 0x01 0x00 0x00 0x00 0x00 0x7d 0x01 0x00 0x00 0x01 0x01 0x00 0x7e 0x01 0x00 0x00 0x01 0x01 0x00 0x7f 0x01 0x00 0x00 0x01 0x01 0x00 0x80 0x01 0x00 0x00 0x01 0x01 0x00 0x81 0x01 0x00 0x00 0x01 0x01 0x00 0x82 0x01 0x00 0x00 0x01 0x01 0x00 0x83 0x01 0x00 0x00 0x01 0x00 0x00 0x84 0x01 0x00 0x00 0x01 0x01 0x00 0x85 0x01 0x01 0x01 0x00 0x00 0x00 0x86 0x01 0x00 0x00 0x01 0x00 0x01 0x87 0x01 0x01 0x00 0x00 0x00 0x00 0x88 0x01 0x01 0x00 0x01 0x00 0x00 0x89 0x01 0x01 0x00 0x01 0x00 0x00 0x8a 0x01 0x01 0x00 0x00 0x00 0x00 0x8b 0x01 0x01 0x00 0x01 0x00 0x00 0x8c 0x01 0x00 0x00 0x00 0x00 0x00 0x8d 0x01 0x00 0x00 0x00 0x00 0x00 0x8e 0x01 0x00 0x00 0x00 0x00 0x00 0x8f 0x01 0x00 0x00 0x00 0x00 0x00 0x90 0x01 0x00 0x00 0x01 0x00 0x00 0x91 0x01 0x01 0x01 0x00 0x00 0x00 0x92 0x01 0x00 0x00 0x01 0x00 0x00 0x93 0x01 0x01 0x00 0x00 0x00 0x00 0x94 0x01 0x01 0x00 0x00 0x00 0x00 0x95 0x01 0x01 0x00 0x00 0x00 0x00 0x96 0x00 0x01 0x00 0x00 0x00 0x00 0x97 0x00 0x01 0x00 0x00 0x00 0x00 0x98 0x00 0x01 0x00 0x00 0x00 0x00 0x99 0x00 0x01 0x00 0x00 0x00 0x00 0x9a 0x01 0x00 0x00 0x00 0x00 0x00 0x9b 0x00 0x00 0x00 0x01 0x00 0x00 0x9c 0x00 0x00 0x00 0x01 0x00 0x00 0x9d 0x00 0x00 0x00 0x01 0x00 0x00 0x9e 0x00 0x01 0x00 0x00 0x00 0x00 0x9f 0x00 0x00 0x00 0x01 0x01 0x00 0xa0 0x00 0x00 0x00 0x01 0x01 0x00 0xa1 0x02 0x00 0x00 0x01 0x00 0x00 0xa2 0x02 0x01 0x01 0x00 0x00 0x00 0xa3 0x02 0x01 0x00 0x00 0x00 0x00 0xa4 0x02 0x01 0x00 0x00 0x00 0x00 0xa5 0x00 0x01 0x00 0x00 0x00 0x00 0xa6 0x00 0x00 0x00 0x01 0x00 0x00 0xa7 0x01 0x01 0x00 0x01 0x00 0x00 0xa8 0x01 0x01 0x00 0x01 0x00 0x00 0xa9 0x00 0x01 0x00 0x00 0x00 0x00 0xaa 0x00 0x00 0x00 0x00 0x00 0x00 0xab 0x00 0x00 0x00 0x00 0x00 0x00 0xac 0x00 0x00 0x00 0x00 0x00 0x00 0xad 0x00 0x00 0x00 0x01 0x00 0x00 0xae 0x00 0x00 0x00 0x01 0x00 0x00 0xaf 0x00 0x00 0x00 0x00 0x00 0x00 0xb0 0x00 0x00 0x00 0x01 0x00 0x00 0xb1 0x00 0x01 0x00 0x00 0x00 0x00 0xb2 0x00 0x00 0x00 0x01 0x00 0x00 0xb3 0x00 0x00 0x00 0x01 0x00 0x00 0xb4 0x00 0x00 0x00 0x01 0x00 0x00 0xb5 0x00 0x00 0x00 0x01 0x00 0x00 0xb6 0x00 0x00 0x00 0x01 0x00 0x00 0xb7 0x00 0x00 0x00 0x01 0x00 0x00 0xb8 0x00 0x00 0x00 0x01 0x00 0x00 0xb9 0x00 0x00 0x00 0x01 0x00 0x00 0xba 0x00 0x00 0x00 0x01 0x00 0x00 0xbb 0x00 0x00 0x00 0x01 0x00 0x00 0xbc 0x00 0x00 0x00 0x01 0x00 0x00 0xbd 0x00 0x00 0x00 0x01 0x00 0x00 0xbe 0x00 0x00 0x00 0x01 0x00 0x00 0xbf 0x00 0x00 0x00 0x01 0x00 0x00>;
		};
	};

	fragment@56 {
		target = <0xffffffff>;

		__overlay__ {
			deb-gpios = <0xffffffff 0x00 0x00>;
			debounce = <0x7d000>;
			interrupt-parent = <0xffffffff>;
			interrupts = <0x00 0x08 0x00 0x00>;
			status = "okay";
		};
	};

	fragment@57 {
		target = <0xffffffff>;

		__overlay__ {
			interrupt-parent = <0xffffffff>;
			interrupts = <0x01 0x02 0x01 0x00>;
			status = "okay";
		};
	};

	fragment@58 {
		target = <0xffffffff>;

		__overlay__ {
			deb-gpios = <0xffffffff 0x03 0x00>;
			debounce = <0x3e800>;
			interrupt-parent = <0xffffffff>;
			interrupts = <0x03 0x08 0x03 0x00>;
			status = "okay";
		};
	};

	fragment@59 {
		target = <0xffffffff>;

		__overlay__ {
			interrupt-parent = <0xffffffff>;
			interrupts = <0x04 0x08 0x04 0x00>;
			status = "okay";
		};
	};

	fragment@6 {
		target = <0xffffffff>;

		__overlay__ {

			gpio_id0_default {
				phandle = <0x0e>;

				pins_cmd_dat {
					bias-pull-up = <0x00>;
					input-enable;
					pinmux = <0xa600>;
					slew-rate = <0x00>;
				};
			};
		};
	};

	fragment@60 {
		target = <0xffffffff>;

		__overlay__ {
			interrupt-parent = <0xffffffff>;
			interrupts = <0x05 0x04 0x05 0x00>;
			status = "okay";
		};
	};

	fragment@61 {
		target = <0xffffffff>;

		__overlay__ {
			deb-gpios = <0xffffffff 0x07 0x00>;
			debounce = <0x3e800>;
			interrupt-parent = <0xffffffff>;
			interrupts = <0x07 0x08 0x07 0x00>;
			status = "okay";
		};
	};

	fragment@62 {
		target = <0xffffffff>;

		__overlay__ {
			interrupt-parent = <0xffffffff>;
			interrupts = <0x09 0x08 0x09 0x00>;
			status = "okay";
		};
	};

	fragment@63 {
		target = <0xffffffff>;

		__overlay__ {
			interrupt-parent = <0xffffffff>;
			interrupts = <0x0a 0x08 0x0a 0x00>;
			status = "okay";
		};
	};

	fragment@64 {
		target = <0xffffffff>;

		__overlay__ {
			interrupt-parent = <0xffffffff>;
			interrupts = <0x16 0x08 0x16 0x00>;
			status = "okay";
		};
	};

	fragment@65 {
		target = <0xffffffff>;

		__overlay__ {
			interrupt-parent = <0xffffffff>;
			interrupts = <0x29 0x08 0x29 0x00>;
			status = "okay";
		};
	};

	fragment@66 {
		target = <0xffffffff>;

		__overlay__ {
			interrupt-parent = <0xffffffff>;
			interrupts = <0x2c 0x01 0x2c 0x01>;
			status = "okay";
		};
	};

	fragment@67 {
		target = <0xffffffff>;

		__overlay__ {
			interrupt-parent = <0xffffffff>;
			interrupts = <0xb6 0x04 0xbe 0x00>;
			status = "okay";
		};
	};

	fragment@68 {
		target = <0xffffffff>;

		__overlay__ {
			interrupt-parent = <0xffffffff>;
			interrupts = <0xba 0x08 0xad 0x00>;
			status = "okay";
		};
	};

	fragment@69 {
		target = <0xffffffff>;

		__overlay__ {
			compatible = "mediatek,md1_sim1_hot_plug_eint-eint";
			debounce = <0x00 0x186a0>;
			dedicated = <0x00 0x00>;
			interrupts = <0x00 0x08>;
			sockettype = <0x00 0x00>;
			src_pin = <0x00 0x01>;
			status = "okay";
		};
	};

	fragment@7 {
		target = <0xffffffff>;

		__overlay__ {
			oppo,fp-id0 = <0xffffffff 0xa6 0x00>;
			pinctrl-0 = <0x0e>;
			pinctrl-names = "default";
		};
	};

	fragment@70 {
		target = <0xffffffff>;

		__overlay__ {
			compatible = "mediatek,md1_sim2_hot_plug_eint-eint";
			debounce = <0x01 0x186a0>;
			dedicated = <0x01 0x00>;
			interrupts = <0x01 0x08>;
			sockettype = <0x01 0x00>;
			src_pin = <0x01 0x02>;
			status = "okay";
		};
	};

	fragment@71 {
		target = <0xffffffff>;

		__overlay__ {
			regulator-default-on = <0x01>;
			regulator-name = "vcama1";
			status = "okay";
		};
	};

	fragment@72 {
		target = <0xffffffff>;

		__overlay__ {
			regulator-default-on = <0x01>;
			regulator-name = "vcama2";
			status = "okay";
		};
	};

	fragment@73 {
		target = <0xffffffff>;

		__overlay__ {
			regulator-default-on = <0x01>;
			regulator-name = "vsim1";
			status = "okay";
		};
	};

	fragment@74 {
		target = <0xffffffff>;

		__overlay__ {
			regulator-default-on = <0x01>;
			regulator-name = "vsim2";
			status = "okay";
		};
	};

	fragment@75 {
		target = <0xffffffff>;

		__overlay__ {
			regulator-default-on = <0x01>;
			regulator-name = "vcamd";
			status = "okay";
		};
	};

	fragment@76 {
		target = <0xffffffff>;

		__overlay__ {
			regulator-default-on = <0x01>;
			regulator-name = "vcamio";
			status = "okay";
		};
	};

	fragment@77 {
		target = <0xffffffff>;

		__overlay__ {
			regulator-default-on = <0x01>;
			regulator-name = "vldo28";
			status = "okay";
		};
	};

	fragment@78 {
		target = <0xffffffff>;

		__overlay__ {
			status = "okay";
			vcama_main2-supply = <0xffffffff>;
			vcama_sub-supply = <0xffffffff>;
			vcamaf-supply = <0xffffffff>;
			vcamaf_main2-supply = <0xffffffff>;
			vcamaf_sub-supply = <0xffffffff>;
			vcamd-supply = <0xffffffff>;
			vcamio-supply = <0xffffffff>;
			vcamio_main2-supply = <0xffffffff>;
			vcamio_sub-supply = <0xffffffff>;
		};
	};

	fragment@79 {
		target = <0xffffffff>;

		__overlay__ {
			status = "okay";
			vtouch-supply = <0xffffffff>;
		};
	};

	fragment@8 {
		target = <0xffffffff>;

		__overlay__ {

			phy_tuning {
				compatible = "mediatek,phy_tuning";
				u2_enhance = <0x02>;
				u2_term_ref = <0x07>;
				u2_vrt_ref = <0x07>;
			};
		};
	};

	fragment@80 {
		target = <0xffffffff>;

		__overlay__ {
			mediatek,kpd-hw-dl-key0 = <0x11>;
			mediatek,kpd-hw-dl-key1 = <0x01>;
			mediatek,kpd-hw-dl-key2 = <0x08>;
			mediatek,kpd-hw-init-map = <0x00 0x72 0x00 0x00 0x00 0x00 0x00 0x00 0x00 0x00 0x00 0x00 0x00 0x00 0x00 0x00 0x00 0x00 0x00 0x00 0x00 0x00 0x00 0x00 0x00 0x00 0x00 0x00 0x00 0x00 0x00 0x00 0x00 0x00 0x00 0x00 0x00 0x00 0x00 0x00 0x00 0x00 0x00 0x00 0x00 0x00 0x00 0x00 0x00 0x00 0x00 0x00 0x00 0x00 0x00 0x00 0x00 0x00 0x00 0x00 0x00 0x00 0x00 0x00 0x00 0x00 0x00 0x00 0x00 0x00 0x00 0x00>;
			mediatek,kpd-hw-map-num = <0x48>;
			mediatek,kpd-hw-pwrkey = <0x08>;
			mediatek,kpd-hw-recovery-key = <0x01>;
			mediatek,kpd-hw-rstkey = <0x11>;
			mediatek,kpd-key-debounce = <0x400>;
			mediatek,kpd-pwkey-gpio-din = <0x00>;
			mediatek,kpd-pwrkey-eint-gpio = <0x00>;
			mediatek,kpd-sw-pwrkey = <0x74>;
			mediatek,kpd-sw-rstkey = <0x73>;
			mediatek,kpd-use-extend-type = <0x00>;
			status = "okay";
		};
	};

	fragment@81 {
		target = <0xffffffff>;

		__overlay__ {

			cam0@0 {
				phandle = <0x3c>;

				pins_cmd_dat {
					output-low;
					pinmux = <0x6500>;
					slew-rate = <0x01>;
				};
			};

			cam0@1 {
				phandle = <0x3d>;

				pins_cmd_dat {
					output-high;
					pinmux = <0x6500>;
					slew-rate = <0x01>;
				};
			};

			cam0@2 {
				phandle = <0x3e>;

				pins_cmd_dat {
					output-low;
					pinmux = <0x6100>;
					slew-rate = <0x01>;
				};
			};

			cam0@3 {
				phandle = <0x3f>;

				pins_cmd_dat {
					output-high;
					pinmux = <0x6100>;
					slew-rate = <0x01>;
				};
			};

			cam0@vcam0 {
				phandle = <0x48>;

				pins_cmd_dat {
					output-low;
					pinmux = <0xb100>;
					slew-rate = <0x01>;
				};
			};

			cam0@vcam1 {
				phandle = <0x49>;

				pins_cmd_dat {
					output-high;
					pinmux = <0xb100>;
					slew-rate = <0x01>;
				};
			};

			cam1@0 {
				phandle = <0x40>;

				pins_cmd_dat {
					output-low;
					pinmux = <0x6200>;
					slew-rate = <0x01>;
				};
			};

			cam1@1 {
				phandle = <0x41>;

				pins_cmd_dat {
					output-high;
					pinmux = <0x6200>;
					slew-rate = <0x01>;
				};
			};

			cam1@2 {
				phandle = <0x42>;

				pins_cmd_dat {
					output-low;
					pinmux = <0x6600>;
					slew-rate = <0x01>;
				};
			};

			cam1@3 {
				phandle = <0x43>;

				pins_cmd_dat {
					output-high;
					pinmux = <0x6600>;
					slew-rate = <0x01>;
				};
			};

			cam1@vcam0 {
				phandle = <0x4a>;

				pins_cmd_dat {
					output-low;
					pinmux = <0xa900>;
					slew-rate = <0x01>;
				};
			};

			cam1@vcam1 {
				phandle = <0x4b>;

				pins_cmd_dat {
					output-high;
					pinmux = <0xa900>;
					slew-rate = <0x01>;
				};
			};

			cam2@0 {
				phandle = <0x44>;

				pins_cmd_dat {
					output-low;
					pinmux = <0x6d00>;
					slew-rate = <0x01>;
				};
			};

			cam2@1 {
				phandle = <0x45>;

				pins_cmd_dat {
					output-high;
					pinmux = <0x6d00>;
					slew-rate = <0x01>;
				};
			};

			cam2@3 {
				phandle = <0x46>;

				pins_cmd_dat {
					output-low;
					pinmux = <0x6b00>;
					slew-rate = <0x01>;
				};
			};

			cam2@4 {
				phandle = <0x47>;

				pins_cmd_dat {
					output-high;
					pinmux = <0x6b00>;
					slew-rate = <0x01>;
				};
			};

			camdefault {
				phandle = <0x3b>;
			};

			camera0_mclk_2mA@gpio99 {
				phandle = <0x4d>;

				pins_cmd_dat {
					drive-strength = <0x00>;
					pinmux = <0x6301>;
				};
			};

			camera0_mclk_4mA@gpio99 {
				phandle = <0x4e>;

				pins_cmd_dat {
					drive-strength = <0x01>;
					pinmux = <0x6301>;
				};
			};

			camera0_mclk_6mA@gpio99 {
				phandle = <0x4f>;

				pins_cmd_dat {
					drive-strength = <0x02>;
					pinmux = <0x6301>;
				};
			};

			camera0_mclk_8mA@gpio99 {
				phandle = <0x50>;

				pins_cmd_dat {
					drive-strength = <0x03>;
					pinmux = <0x6301>;
				};
			};

			camera0_mclk_gpio_mode@gpio99 {
				phandle = <0x4c>;

				pins_cmd_dat {
					drive-strength = <0x01>;
					pinmux = <0x6300>;
				};
			};

			camera1_mclk_2mA@gpio100 {
				phandle = <0x52>;

				pins_cmd_dat {
					drive-strength = <0x00>;
					pinmux = <0x6401>;
				};
			};

			camera1_mclk_4mA@gpio100 {
				phandle = <0x53>;

				pins_cmd_dat {
					drive-strength = <0x01>;
					pinmux = <0x6401>;
				};
			};

			camera1_mclk_6mA@gpio100 {
				phandle = <0x54>;

				pins_cmd_dat {
					drive-strength = <0x02>;
					pinmux = <0x6401>;
				};
			};

			camera1_mclk_8mA@gpio100 {
				phandle = <0x55>;

				pins_cmd_dat {
					drive-strength = <0x03>;
					pinmux = <0x6401>;
				};
			};

			camera1_mclk_gpio_mode@gpio100 {
				phandle = <0x51>;

				pins_cmd_dat {
					drive-strength = <0x01>;
					pinmux = <0x6400>;
				};
			};

			camera2_mclk_2mA@gpio108 {
				phandle = <0x57>;

				pins_cmd_dat {
					drive-strength = <0x00>;
					pinmux = <0x6c01>;
				};
			};

			camera2_mclk_4mA@gpio108 {
				phandle = <0x58>;

				pins_cmd_dat {
					drive-strength = <0x01>;
					pinmux = <0x6c01>;
				};
			};

			camera2_mclk_6mA@gpio108 {
				phandle = <0x59>;

				pins_cmd_dat {
					drive-strength = <0x02>;
					pinmux = <0x6c01>;
				};
			};

			camera2_mclk_8mA@gpio108 {
				phandle = <0x5a>;

				pins_cmd_dat {
					drive-strength = <0x03>;
					pinmux = <0x6c01>;
				};
			};

			camera2_mclk_gpio_mode@gpio108 {
				phandle = <0x56>;

				pins_cmd_dat {
					drive-strength = <0x01>;
					pinmux = <0x6c00>;
				};
			};

			camera_pins_cami2c_pullup_disable@i2c {
				phandle = <0x5c>;

				pins_cmd_dat0 {
					bias-disable;
					pinmux = <0x6701>;
					slew-rate = <0x00>;
				};

				pins_cmd_dat1 {
					bias-disable;
					pinmux = <0x6801>;
					slew-rate = <0x00>;
				};

				pins_cmd_dat2 {
					bias-disable;
					pinmux = <0x6901>;
					slew-rate = <0x00>;
				};

				pins_cmd_dat3 {
					bias-disable;
					pinmux = <0x6a01>;
					slew-rate = <0x00>;
				};
			};

			camera_pins_cami2c_pullup_enable@i2c {
				phandle = <0x5b>;

				pins_cmd_dat0 {
					bias-pull-up;
					pinmux = <0x6701>;
					slew-rate = <0x00>;
				};

				pins_cmd_dat1 {
					bias-pull-up;
					pinmux = <0x6801>;
					slew-rate = <0x00>;
				};

				pins_cmd_dat2 {
					bias-pull-up;
					pinmux = <0x6901>;
					slew-rate = <0x00>;
				};

				pins_cmd_dat3 {
					bias-pull-up;
					pinmux = <0x6a01>;
					slew-rate = <0x00>;
				};
			};
		};
	};

	fragment@82 {
		target = <0xffffffff>;

		__overlay__ {
			cam0_enable_sensor = "s5k3l6_main_qt_mipi_raw s5k3l6_main_ts_mipi_raw";
			cam0_vcamaf-supply = <0xffffffff>;
			cam0_vcamd-supply = <0xffffffff>;
			cam0_vcamio-supply = <0xffffffff>;
			cam1_enable_sensor = "s5k3l6_sub_qt_mipi_raw s5k3l6_sub_ly_mipi_raw gc13c33_mipi_raw";
			cam1_vcama-supply = <0xffffffff>;
			cam1_vcamio-supply = <0xffffffff>;
			cam2_enable_sensor = "gc2375_jk_mipi_raw sp2509_hl_mipi_raw";
			cam2_vcama-supply = <0xffffffff>;
			cam2_vcamio-supply = <0xffffffff>;
			pinctrl-0 = <0x3b>;
			pinctrl-1 = <0x3c>;
			pinctrl-10 = <0x45>;
			pinctrl-11 = <0x46>;
			pinctrl-12 = <0x47>;
			pinctrl-13 = <0x48>;
			pinctrl-14 = <0x49>;
			pinctrl-15 = <0x4a>;
			pinctrl-16 = <0x4b>;
			pinctrl-17 = <0x4c>;
			pinctrl-18 = <0x4d>;
			pinctrl-19 = <0x4e>;
			pinctrl-2 = <0x3d>;
			pinctrl-20 = <0x4f>;
			pinctrl-21 = <0x50>;
			pinctrl-22 = <0x51>;
			pinctrl-23 = <0x52>;
			pinctrl-24 = <0x53>;
			pinctrl-25 = <0x54>;
			pinctrl-26 = <0x55>;
			pinctrl-27 = <0x56>;
			pinctrl-28 = <0x57>;
			pinctrl-29 = <0x58>;
			pinctrl-3 = <0x3e>;
			pinctrl-30 = <0x59>;
			pinctrl-31 = <0x5a>;
			pinctrl-32 = <0x5b>;
			pinctrl-33 = <0x5c>;
			pinctrl-4 = <0x3f>;
			pinctrl-5 = <0x40>;
			pinctrl-6 = <0x41>;
			pinctrl-7 = <0x42>;
			pinctrl-8 = <0x43>;
			pinctrl-9 = <0x44>;
			pinctrl-names = "default\0cam0_rst0\0cam0_rst1\0cam0_pnd0\0cam0_pnd1\0cam1_pnd0\0cam1_pnd1\0cam1_rst0\0cam1_rst1\0cam2_rst0\0cam2_rst1\0cam2_pnd0\0cam2_pnd1\0cam0_ldo_vcama_0\0cam0_ldo_vcama_1\0cam1_ldo_vcamd_0\0cam1_ldo_vcamd_1\0cam0_mclk_off\0cam0_mclk_2mA\0cam0_mclk_4mA\0cam0_mclk_6mA\0cam0_mclk_8mA\0cam1_mclk_off\0cam1_mclk_2mA\0cam1_mclk_4mA\0cam1_mclk_6mA\0cam1_mclk_8mA\0cam2_mclk_off\0cam2_mclk_2mA\0cam2_mclk_4mA\0cam2_mclk_6mA\0cam2_mclk_8mA\0cami2c_pullup_enable\0cami2c_pullup_disable";
			status = "okay";
		};
	};

	fragment@9 {
		target = <0xffffffff>;

		__overlay__ {
			core_1 = "enable";
			scp_sramSize = <0x80000>;
		};
	};
};
